VERSION ""

NS_ :

BS_:

BU_: TBox

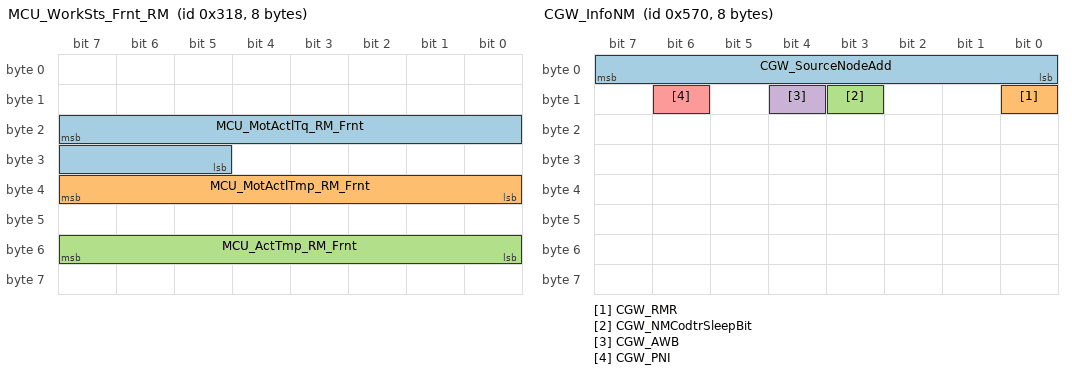
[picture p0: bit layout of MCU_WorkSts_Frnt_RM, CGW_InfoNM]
BO_ 792 MCU_WorkSts_Frnt_RM: 8 CGW
 SG_ MCU_MotActlTq_RM_Frnt : 23|11@0+ (0.5,-500) [-500|500] "Nm" TBox
 SG_ MCU_MotActlTmp_RM_Frnt : 39|8@0+ (1,-40) [-40|214] "degree C" TBox
 SG_ MCU_ActTmp_RM_Frnt : 55|8@0+ (1,-40) [-40|214] "degree C" TBox

BO_ 1392 CGW_InfoNM: 8 CGW
 SG_ CGW_SourceNodeAdd : 7|8@0+ (1,0) [112|112] "" TBox,HU,AMP
 SG_ CGW_RMR : 8|1@0+ (1,0) [0|1] "" TBox,HU,AMP
 SG_ CGW_NMCodtrSleepBit : 11|1@0+ (1,0) [0|1] "" TBox,HU,AMP
 SG_ CGW_AWB : 12|1@0+ (1,0) [0|1] "" TBox,HU,AMP
 SG_ CGW_PNI : 14|1@0+ (1,0) [0|1] "" TBox,HU,AMP

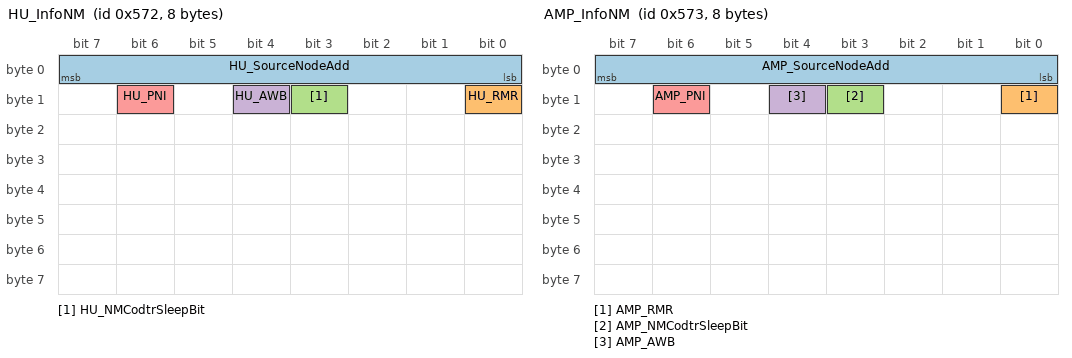
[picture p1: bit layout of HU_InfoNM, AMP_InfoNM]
BO_ 1394 HU_InfoNM: 8 HU
 SG_ HU_SourceNodeAdd : 7|8@0+ (1,0) [114|114] "" TBox,AMP,CGW
 SG_ HU_RMR : 8|1@0+ (1,0) [0|1] "" TBox,AMP,CGW
 SG_ HU_NMCodtrSleepBit : 11|1@0+ (1,0) [0|1] "" TBox,AMP,CGW
 SG_ HU_AWB : 12|1@0+ (1,0) [0|1] "" TBox,AMP,CGW
 SG_ HU_PNI : 14|1@0+ (1,0) [0|1] "" TBox,AMP,CGW

BO_ 1395 AMP_InfoNM: 8 AMP
 SG_ AMP_SourceNodeAdd : 7|8@0+ (1,0) [115|115] "" TBox,HU,CGW
 SG_ AMP_RMR : 8|1@0+ (1,0) [0|1] "" TBox,HU,CGW
 SG_ AMP_NMCodtrSleepBit : 11|1@0+ (1,0) [0|1] "" TBox,HU,CGW
 SG_ AMP_AWB : 12|1@0+ (1,0) [0|1] "" TBox,HU,CGW
 SG_ AMP_PNI : 14|1@0+ (1,0) [0|1] "" TBox,HU,CGW

BO_ 284 VCU_HUDisp_1: 8 CGW
 SG_ VCU_ChrgStsIndcr : 7|1@0+ (1,0) [0|1] "" TBox,HU,AMP
 SG_ VCU_ChrgConnectIndcr : 6|1@0+ (1,0) [0|1] "" TBox,HU

BO_ 285 VCU_HUDisp_2: 8 CGW
 SG_ VCU_VhclResidualMile : 7|10@0+ (1,0) [0|600] "km" TBox,HU

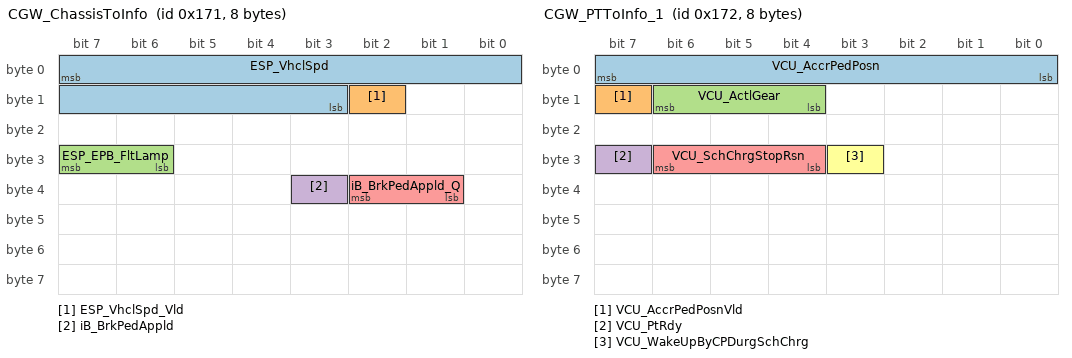
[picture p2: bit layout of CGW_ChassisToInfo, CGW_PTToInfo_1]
BO_ 369 CGW_ChassisToInfo: 8 CGW
 SG_ ESP_VhclSpd : 7|13@0+ (0.05625,0) [0|300] "km/h" TBox,HU,AMP,PAS
 SG_ ESP_VhclSpd_Vld : 10|1@0+ (1,0) [0|1] "" TBox,HU,AMP,PAS
 SG_ ESP_EPB_FltLamp : 31|2@0+ (1,0) [0|3] "" TBox,HU,PAS
 SG_ iB_BrkPedAppld : 35|1@0+ (1,0) [0|1] "" TBox
 SG_ iB_BrkPedAppld_Q : 34|2@0+ (1,0) [0|3] "" TBox

BO_ 370 CGW_PTToInfo_1: 8 CGW
 SG_ VCU_AccrPedPosn : 7|8@0+ (0.4,0) [0|100] "%" TBox
 SG_ VCU_AccrPedPosnVld : 15|1@0+ (1,0) [0|1] "" TBox
 SG_ VCU_ActlGear : 14|3@0+ (1,0) [0|7] "" TBox,HU,AMP,PAS
 SG_ VCU_PtRdy : 31|1@0+ (1,0) [0|1] "" TBox,HU,AMP,PAS
 SG_ VCU_SchChrgStopRsn : 30|3@0+ (1,0) [0|7] "" TBox,HU
 SG_ VCU_WakeUpByCPDurgSchChrg : 27|1@0+ (1,0) [0|1] "" TBox

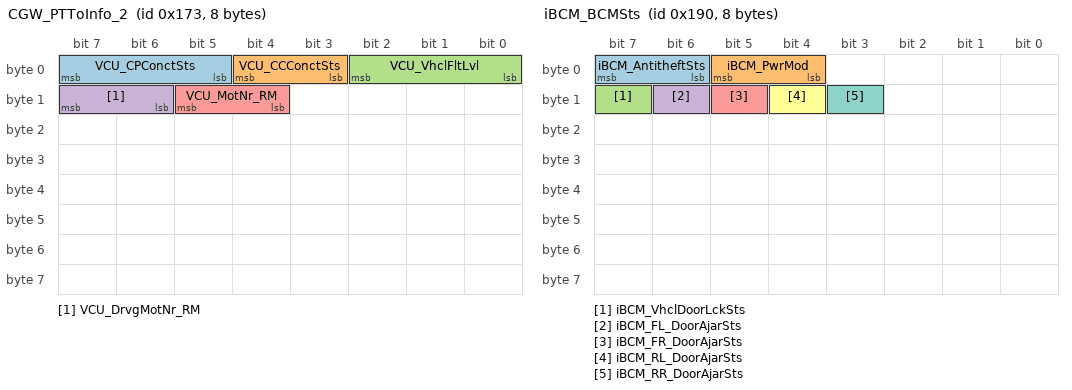
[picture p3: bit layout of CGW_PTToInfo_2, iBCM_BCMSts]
BO_ 371 CGW_PTToInfo_2: 8 CGW
 SG_ VCU_CPConctSts : 7|3@0+ (1,0) [0|7] "" TBox
 SG_ VCU_CCConctSts : 4|2@0+ (1,0) [0|3] "" TBox
 SG_ VCU_VhclFltLvl : 2|3@0+ (1,0) [0|7] "" TBox,HU
 SG_ VCU_DrvgMotNr_RM : 15|2@0+ (1,0) [0|3] "" TBox
 SG_ VCU_MotNr_RM : 13|2@0+ (1,0) [0|3] "" TBox

BO_ 400 iBCM_BCMSts: 8 CGW
 SG_ iBCM_AntitheftSts : 7|2@0+ (1,0) [0|3] "" TBox,HU
 SG_ iBCM_PwrMod : 5|2@0+ (1,0) [0|3] "" TBox,HU,PAS
 SG_ iBCM_VhclDoorLckSts : 15|1@0+ (1,0) [0|1] "" TBox,HU
 SG_ iBCM_FL_DoorAjarSts : 14|1@0+ (1,0) [0|1] "" TBox,HU
 SG_ iBCM_FR_DoorAjarSts : 13|1@0+ (1,0) [0|1] "" TBox,HU
 SG_ iBCM_RL_DoorAjarSts : 12|1@0+ (1,0) [0|1] "" TBox,HU
 SG_ iBCM_RR_DoorAjarSts : 11|1@0+ (1,0) [0|1] "" TBox,HU

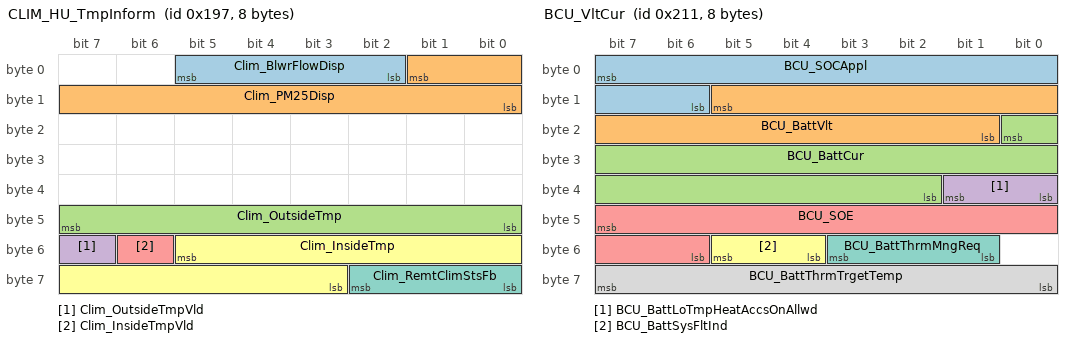
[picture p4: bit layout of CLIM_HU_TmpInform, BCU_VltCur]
BO_ 407 CLIM_HU_TmpInform: 8 CGW
 SG_ Clim_BlwrFlowDisp : 5|4@0+ (1,0) [0|15] "" TBox,HU
 SG_ Clim_PM25Disp : 1|10@0+ (1,0) [0|999] "ug/m3" TBox,HU
 SG_ Clim_OutsideTmp : 47|8@0+ (1,-40) [-40|215] "℃" TBox,PAS
 SG_ Clim_OutsideTmpVld : 55|1@0+ (1,0) [0|1] "" TBox,PAS
 SG_ Clim_InsideTmpVld : 54|1@0+ (1,0) [0|1] "" TBox
 SG_ Clim_InsideTmp : 53|11@0+ (0.1,-40) [-40|120] "℃" TBox
 SG_ Clim_RemtClimStsFb : 58|3@0+ (1,0) [0|7] "" TBox

BO_ 529 BCU_VltCur: 8 CGW
 SG_ BCU_SOCAppl : 7|10@0+ (0.1,0) [0|100] "%" TBox
 SG_ BCU_BattVlt : 13|13@0+ (0.1,0) [0|500] "V" TBox,HU
 SG_ BCU_BattCur : 16|15@0+ (0.1,-1200) [-1200|1200] "A" TBox,HU
 SG_ BCU_BattLoTmpHeatAccsOnAllwd : 33|2@0+ (1,0) [0|3] "" TBox
 SG_ BCU_SOE : 47|10@0+ (0.1,0) [0|100] "%" TBox
 SG_ BCU_BattSysFltInd : 53|2@0+ (1,0) [0|3] "" TBox
 SG_ BCU_BattThrmMngReq : 51|3@0+ (1,0) [0|7] "" TBox
 SG_ BCU_BattThrmTrgetTemp : 63|8@0+ (1,-40) [-40|120] "℃" TBox

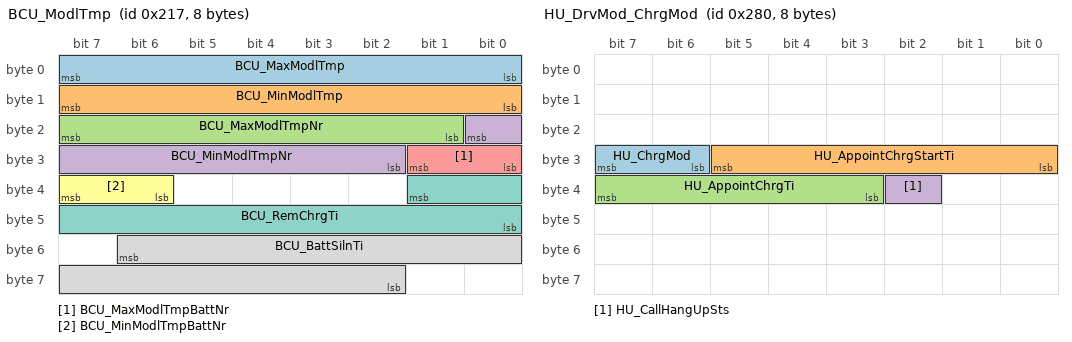
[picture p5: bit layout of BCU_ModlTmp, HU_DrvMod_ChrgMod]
BO_ 535 BCU_ModlTmp: 8 CGW
 SG_ BCU_MaxModlTmp : 7|8@0+ (1,-40) [-40|120] "℃" TBox
 SG_ BCU_MinModlTmp : 15|8@0+ (1,-40) [-40|120] "℃" TBox
 SG_ BCU_MaxModlTmpNr : 23|7@0+ (1,0) [0|120] "" TBox
 SG_ BCU_MinModlTmpNr : 16|7@0+ (1,0) [0|120] "" TBox
 SG_ BCU_MaxModlTmpBattNr : 25|2@0+ (1,0) [0|3] "" TBox
 SG_ BCU_MinModlTmpBattNr : 39|2@0+ (1,0) [0|3] "" TBox
 SG_ BCU_RemChrgTi : 33|10@0+ (1,0) [0|1023] "min" TBox,HU
 SG_ BCU_BattSilnTi : 54|13@0+ (0.1,0) [0|800] "min" TBox

BO_ 536 BCU_WarnInfo: 8 CGW
 SG_ BCU_REESSFaultNr_RM : 7|8@0+ (1,0) [0|254] "" TBox
 SG_ BCU_SOH : 14|7@0+ (1,0) [0|100] "%" TBox
 SG_ BCU_BattOverTmp : 15|1@0+ (1,0) [0|1] "" TBox,HU
 SG_ BCU_CellTmpOverWarn : 16|1@0+ (1,0) [0|1] "" TBox
 SG_ BCU_CellVltUdrWarn : 17|1@0+ (1,0) [0|1] "" TBox
 SG_ BCU_CellVltOverWarn : 18|1@0+ (1,0) [0|1] "" TBox
 SG_ BCU_BattTmpDftlWarn : 19|1@0+ (1,0) [0|1] "" TBox
 SG_ BCU_CellTmpUdrWarn : 20|1@0+ (1,0) [0|1] "" TBox
 SG_ BCU_BattVltUnifWarn : 21|1@0+ (1,0) [0|1] "" TBox
 SG_ BCU_BattVltDftlOverRg : 22|1@0+ (1,0) [0|1] "" TBox
 SG_ BCU_BattVltUdrWarn : 23|1@0+ (1,0) [0|1] "" TBox
 SG_ BCU_BattVltOverWarn : 24|1@0+ (1,0) [0|1] "" TBox
 SG_ BCU_NvMemSts : 25|1@0+ (1,0) [0|1] "" TBox
 SG_ BCU_SOCJumpWarn : 26|1@0+ (1,0) [0|1] "" TBox
 SG_ BCU_SOCOverWarn : 27|1@0+ (1,0) [0|1] "" TBox
 SG_ BCU_SOCLowWarn : 28|1@0+ (1,0) [0|1] "" TBox
 SG_ BCU_BattTmpDftlWarn_RM : 29|1@0+ (1,0) [0|1] "" TBox
 SG_ BCU_REESSNotMatch_RM : 30|1@0+ (1,0) [0|1] "" TBox
 SG_ BCU_OverChrgWarn_RM : 31|1@0+ (1,0) [0|1] "" TBox
 SG_ BCU_ACChrgCntr : 45|11@0+ (1,0) [0|2000] "" TBox
 SG_ BCU_DCChrgrCntr : 50|11@0+ (1,0) [0|2000] "" TBox

BO_ 640 HU_DrvMod_ChrgMod: 8 HU
 SG_ HU_ChrgMod : 31|2@0+ (1,0) [0|3] "" TBox
 SG_ HU_AppointChrgStartTi : 29|6@0+ (1,0) [0|47] "" TBox
 SG_ HU_AppointChrgTi : 39|5@0+ (1,0) [0|23] "" TBox
 SG_ HU_CallHangUpSts : 34|1@0+ (1,0) [0|1] "" TBox

BO_ 641 HU_ESPSwch: 8 HU
 SG_ HU_TotlOdo : 47|24@0+ (0.1,0) [0|999999.9] "km" TBox,CGW

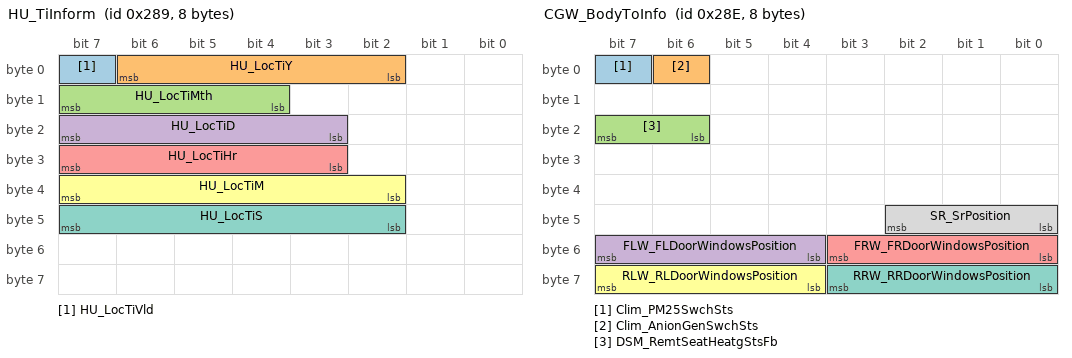
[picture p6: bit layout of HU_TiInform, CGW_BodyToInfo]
BO_ 649 HU_TiInform: 8 HU
 SG_ HU_LocTiVld : 7|1@0+ (1,0) [0|1] "" TBox,CGW
 SG_ HU_LocTiY : 6|5@0+ (1,2019) [2019|2050] "year" TBox,CGW
 SG_ HU_LocTiMth : 15|4@0+ (1,0) [1|12] "month" TBox,CGW
 SG_ HU_LocTiD : 23|5@0+ (1,0) [1|31] "day" TBox,CGW
 SG_ HU_LocTiHr : 31|5@0+ (1,0) [0|23] "hour" TBox,CGW
 SG_ HU_LocTiM : 39|6@0+ (1,0) [0|59] "minute" TBox,CGW
 SG_ HU_LocTiS : 47|6@0+ (1,0) [0|59] "second" TBox,CGW

BO_ 654 CGW_BodyToInfo: 8 CGW
 SG_ Clim_PM25SwchSts : 7|1@0+ (1,0) [0|1] "" TBox
 SG_ Clim_AnionGenSwchSts : 6|1@0+ (1,0) [0|1] "" TBox
 SG_ DSM_RemtSeatHeatgStsFb : 23|2@0+ (1,0) [0|3] "" TBox
 SG_ FLW_FLDoorWindowsPosition : 55|4@0+ (1,0) [0|15] "" TBox,HU
 SG_ FRW_FRDoorWindowsPosition : 51|4@0+ (1,0) [0|15] "" TBox,HU
 SG_ RLW_RLDoorWindowsPosition : 63|4@0+ (1,0) [0|15] "" TBox,HU
 SG_ RRW_RRDoorWindowsPosition : 59|4@0+ (1,0) [0|15] "" TBox,HU
 SG_ SR_SrPosition : 42|3@0+ (1,0) [0|7] "" TBox,HU

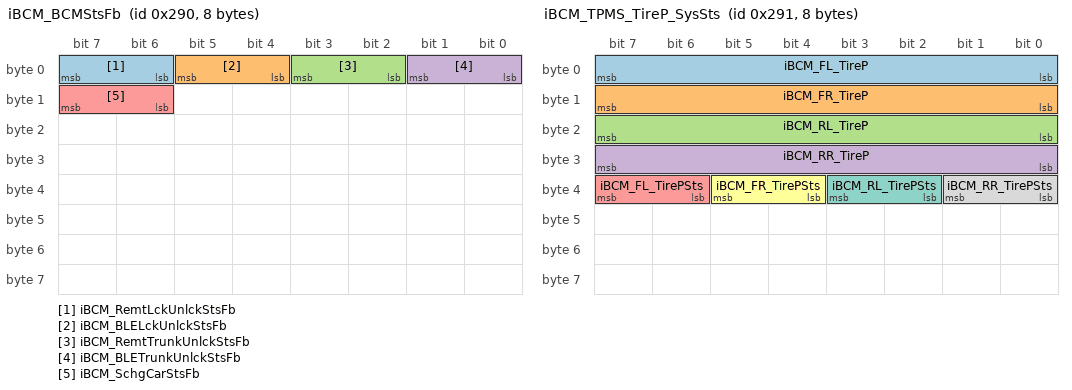
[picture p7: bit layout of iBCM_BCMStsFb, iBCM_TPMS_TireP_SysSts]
BO_ 656 iBCM_BCMStsFb: 8 CGW
 SG_ iBCM_RemtLckUnlckStsFb : 7|2@0+ (1,0) [0|3] "" TBox
 SG_ iBCM_BLELckUnlckStsFb : 5|2@0+ (1,0) [0|3] "" TBox
 SG_ iBCM_RemtTrunkUnlckStsFb : 3|2@0+ (1,0) [0|3] "" TBox
 SG_ iBCM_BLETrunkUnlckStsFb : 1|2@0+ (1,0) [0|3] "" TBox
 SG_ iBCM_SchgCarStsFb : 15|2@0+ (1,0) [0|3] "" TBox

BO_ 657 iBCM_TPMS_TireP_SysSts: 8 CGW
 SG_ iBCM_FL_TireP : 7|8@0+ (1.373,0) [0|348.742] "kpa" TBox,HU
 SG_ iBCM_FR_TireP : 15|8@0+ (1.373,0) [0|348.742] "kpa" TBox,HU
 SG_ iBCM_RL_TireP : 23|8@0+ (1.373,0) [0|348.742] "kpa" TBox,HU
 SG_ iBCM_RR_TireP : 31|8@0+ (1.373,0) [0|348.742] "kpa" TBox,HU
 SG_ iBCM_FL_TirePSts : 39|2@0+ (1,0) [0|3] "" TBox,HU
 SG_ iBCM_FR_TirePSts : 37|2@0+ (1,0) [0|3] "" TBox,HU
 SG_ iBCM_RL_TirePSts : 35|2@0+ (1,0) [0|3] "" TBox,HU
 SG_ iBCM_RR_TirePSts : 33|2@0+ (1,0) [0|3] "" TBox,HU

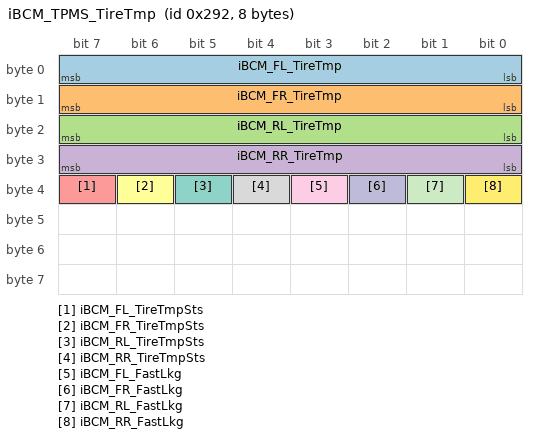
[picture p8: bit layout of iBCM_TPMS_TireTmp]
BO_ 658 iBCM_TPMS_TireTmp: 8 CGW
 SG_ iBCM_FL_TireTmp : 7|8@0+ (1,-50) [-50|204] "℃" TBox,HU
 SG_ iBCM_FR_TireTmp : 15|8@0+ (1,-50) [-50|204] "℃" TBox,HU
 SG_ iBCM_RL_TireTmp : 23|8@0+ (1,-50) [-50|204] "℃" TBox,HU
 SG_ iBCM_RR_TireTmp : 31|8@0+ (1,-50) [-50|204] "℃" TBox,HU
 SG_ iBCM_FL_TireTmpSts : 39|1@0+ (1,0) [0|1] "" TBox,HU
 SG_ iBCM_FR_TireTmpSts : 38|1@0+ (1,0) [0|1] "" TBox,HU
 SG_ iBCM_RL_TireTmpSts : 37|1@0+ (1,0) [0|1] "" TBox,HU
 SG_ iBCM_RR_TireTmpSts : 36|1@0+ (1,0) [0|1] "" TBox,HU
 SG_ iBCM_FL_FastLkg : 35|1@0+ (1,0) [0|1] "" TBox,HU
 SG_ iBCM_FR_FastLkg : 34|1@0+ (1,0) [0|1] "" TBox,HU
 SG_ iBCM_RL_FastLkg : 33|1@0+ (1,0) [0|1] "" TBox,HU
 SG_ iBCM_RR_FastLkg : 32|1@0+ (1,0) [0|1] "" TBox,HU

CM_ SG_ 640 HU_ChrgMod "HU_ChargeMode
充电模式";
CM_ SG_ 640 HU_AppointChrgStartTi "HU_AppointChargeStartTime
充电预约开始时间";
CM_ SG_ 640 HU_AppointChrgTi "HU_AppointChargeTime
预约充电时长";
CM_ SG_ 640 HU_CallHangUpSts "HU_CallHangUpStatus
电话挂断状态";
CM_ SG_ 641 HU_TotlOdo "HU_TotalOdometer
累计里程";
CM_ SG_ 649 HU_LocTiVld "HU_LocalTimeValid
本地时间有效位";
CM_ SG_ 649 HU_LocTiY "HU_LocalTimeYear
本地时间年";
CM_ SG_ 649 HU_LocTiMth "HU_LocalTimeMonth
本地时间月";
CM_ SG_ 649 HU_LocTiD "HU_LocalTimeDay
本地时间日";
CM_ SG_ 649 HU_LocTiHr "HU_LocalTimeHour
本地时间时";
CM_ SG_ 649 HU_LocTiM "HU_LocalTimeMinute
本地时间分";
CM_ SG_ 649 HU_LocTiS "HU_LocalTimeSecond
本地时间秒";
CM_ SG_ 1394 HU_SourceNodeAdd "Source Node Address
原节点地址";
CM_ SG_ 1394 HU_RMR "Repeat message request
重复报文请求";
CM_ SG_ 1394 HU_NMCodtrSleepBit "NM Coordinator Sleep Bit
网络管理协调睡眠指示位";
CM_ SG_ 1394 HU_AWB "Active wakeup bit
主动唤醒指示位";
CM_ SG_ 1394 HU_PNI "Partial netwark information bit 
局部网络指示位";
CM_ SG_ 1395 AMP_SourceNodeAdd "Source Node Address
原节点地址";
CM_ SG_ 1395 AMP_RMR "Repeat message request
重复报文请求";
CM_ SG_ 1395 AMP_NMCodtrSleepBit "NM Coordinator Sleep Bit
网络管理协调睡眠指示位";
CM_ SG_ 1395 AMP_AWB "Active wakeup bit
主动唤醒指示位";
CM_ SG_ 1395 AMP_PNI "Partial netwark information bit 
局部网络指示位";
CM_ SG_ 1392 CGW_SourceNodeAdd "Source Node Address
原节点地址";
CM_ SG_ 1392 CGW_RMR "Repeat message request
重复报文请求";
CM_ SG_ 1392 CGW_NMCodtrSleepBit "NM Coordinator Sleep Bit
网络管理协调睡眠指示位";
CM_ SG_ 1392 CGW_AWB "Active wakeup bit
主动唤醒指示位";
CM_ SG_ 1392 CGW_PNI "Partial netwark information bit 
局部网络指示位";
CM_ SG_ 284 VCU_ChrgStsIndcr "Charge status indicator
充电状态指示";
CM_ SG_ 284 VCU_ChrgConnectIndcr "Charge connect indicator
充电链接指示";
CM_ SG_ 285 VCU_VhclResidualMile "Vehicle residual mileage
剩余续驶里程";
CM_ SG_ 370 VCU_AccrPedPosn "Accelerator Pedal Position";
CM_ SG_ 370 VCU_AccrPedPosnVld "Accelerator Pedal Position Valid";
CM_ SG_ 370 VCU_ActlGear "Actual gear";
CM_ SG_ 370 VCU_PtRdy "Powertrain have ready
动力系统准备就绪";
CM_ SG_ 370 VCU_SchChrgStopRsn "Schedule charging stop reason
预约充电停止充电的原因";
CM_ SG_ 370 VCU_WakeUpByCPDurgSchChrg "VCU is wake up by CP when power net is recovery during schedule charging
预约充电中电网断电再次来电VCU被CP唤醒(仅用于该工况)";
CM_ SG_ 371 VCU_CPConctSts "CP Connection Status
CP状态";
CM_ SG_ 371 VCU_CCConctSts "CC Connection Status
CC状态";
CM_ SG_ 371 VCU_VhclFltLvl "Vehicle Fault Level
整车故障等级";
CM_ SG_ 371 VCU_DrvgMotNr_RM "Driving motor number
驱动电机号";
CM_ SG_ 371 VCU_MotNr_RM "Motor number
电机数量";
CM_ SG_ 792 MCU_MotActlTq_RM_Frnt "Motor actual torque
电机实际扭矩";
CM_ SG_ 792 MCU_MotActlTmp_RM_Frnt "Actual temperature of motor
电机实际温度";
CM_ SG_ 792 MCU_ActTmp_RM_Frnt "MCU actual temperature
电机控制器实际温度";
CM_ SG_ 529 BCU_SOCAppl "Application SOC
电池荷电量(应用SOC)";
CM_ SG_ 529 BCU_BattVlt "Battery Voltage
电池总电压";
CM_ SG_ 529 BCU_BattCur "Battery current
电池总电流";
CM_ SG_ 529 BCU_BattLoTmpHeatAccsOnAllwd "Battery low temperature heating accessory on allowed
电池低温加热附件开启允许";
CM_ SG_ 529 BCU_SOE "SOE
电池剩余电量";
CM_ SG_ 529 BCU_BattSysFltInd "Battery systerm fault indicate
电池系统故障";
CM_ SG_ 529 BCU_BattThrmMngReq "Battery Thermo Management request
电池热管理请求";
CM_ SG_ 529 BCU_BattThrmTrgetTemp "Battery Thermo target temperature
电池热管理目标温度";
CM_ SG_ 535 BCU_MaxModlTmp "Module Max Tempeture
模组最高温度";
CM_ SG_ 535 BCU_MinModlTmp "Module Min Tempeture
模组最低温度";
CM_ SG_ 535 BCU_MaxModlTmpNr "Max module tempeture number
模组最高温度对应的编号";
CM_ SG_ 535 BCU_MinModlTmpNr "Min module tempeture number
模组最低温度对应的编号";
CM_ SG_ 535 BCU_MaxModlTmpBattNr "Max module tempeture battery number
模组最高温度对应点的电池编号";
CM_ SG_ 535 BCU_MinModlTmpBattNr "Min module tempeture battery number
模组最低温度对应点的电池编号";
CM_ SG_ 535 BCU_RemChrgTi "Remain Charging Time
剩余充电时间";
CM_ SG_ 535 BCU_BattSilnTi "Battery Silence Time 
电池静置时间";
CM_ SG_ 536 BCU_REESSFaultNr_RM "Falut number of rechargeable electrical energy storage systerm
可充电储能设备故障总数";
CM_ SG_ 536 BCU_SOH "SOH
电池健康状态";
CM_ SG_ 536 BCU_BattOverTmp "Battery Over Tempeture Waring
动力电池过温报警";
CM_ SG_ 536 BCU_CellTmpOverWarn "Cell Over Tempeture Warning
单体电池温度过高报警";
CM_ SG_ 536 BCU_CellVltUdrWarn "Cell Voltage Under Warning
单体电池欠压报警";
CM_ SG_ 536 BCU_CellVltOverWarn "Cell Voltage Over Warning
单体电池过压报警";
CM_ SG_ 536 BCU_BattTmpDftlWarn "Battery Tempeture Differential Warning
温度差异报警";
CM_ SG_ 536 BCU_CellTmpUdrWarn "Cell Under Tempeture Warning
单体电池温度过低报警";
CM_ SG_ 536 BCU_BattVltUnifWarn "Battery Voltage Uniformity Warning
动力蓄电池一致性差报警";
CM_ SG_ 536 BCU_BattVltDftlOverRg "Battery Voltage Diff Over Range
单体压差过大";
CM_ SG_ 536 BCU_BattVltUdrWarn "Battery Voltage Under Warning
动力电池欠压报警";
CM_ SG_ 536 BCU_BattVltOverWarn "Battery Voltage Over Warning
动力电池过压报警";
CM_ SG_ 536 BCU_NvMemSts "Nonvolatile Memory Status
非易失性存储器状态";
CM_ SG_ 536 BCU_SOCJumpWarn "SOC Jump Warning
SOC跳变报警";
CM_ SG_ 536 BCU_SOCOverWarn "SOC Over Warning
SOC过高报警";
CM_ SG_ 536 BCU_SOCLowWarn "SOC Low Warning
SOC过低报警";
CM_ SG_ 536 BCU_BattTmpDftlWarn_RM "Battery Tempeture Differential Warning
电池温度差异报警";
CM_ SG_ 536 BCU_REESSNotMatch_RM "Rechargeable electrical energy storage systerm not match
可充电储能系统不匹配";
CM_ SG_ 536 BCU_OverChrgWarn_RM "Over charging warning 
过充报警";
CM_ SG_ 536 BCU_ACChrgCntr "AC Charge Counter
慢充累计次数";
CM_ SG_ 536 BCU_DCChrgrCntr "DC Charger Counter
快充累计次数";
CM_ SG_ 369 ESP_VhclSpd "Vehicle speed out";
CM_ SG_ 369 ESP_VhclSpd_Vld "Vehicle speed out status";
CM_ SG_ 369 ESP_EPB_FltLamp "EPB_FailureLamp";
CM_ SG_ 369 iB_BrkPedAppld "Brake pedal is applied";
CM_ SG_ 369 iB_BrkPedAppld_Q "Qualifier of brake pedal applied";
CM_ SG_ 657 iBCM_FL_TireP "TireLeftFrontPressure
左前轮胎压压力";
CM_ SG_ 657 iBCM_FR_TireP "TireRightFrontPressure
右前轮胎压压力";
CM_ SG_ 657 iBCM_RL_TireP "TireLeftRearPressure
左后轮胎压压力";
CM_ SG_ 657 iBCM_RR_TireP "TireRightRearPressure
右后轮胎压压力";
CM_ SG_ 657 iBCM_FL_TirePSts "TireLeftFrontPressureStatus
左前轮胎压状态";
CM_ SG_ 657 iBCM_FR_TirePSts "TireRightFrontPressureStatus
右前轮胎压状态";
CM_ SG_ 657 iBCM_RL_TirePSts "TireLeftRearPressureStatus
左后轮胎压状态";
CM_ SG_ 657 iBCM_RR_TirePSts "TireRightRearPressureStatus
右后轮胎压状态";
CM_ SG_ 658 iBCM_FL_TireTmp "TireLeftFrontTemperature
左前轮胎温";
CM_ SG_ 658 iBCM_FR_TireTmp "TireRightFrontTemperature
右前轮胎温";
CM_ SG_ 658 iBCM_RL_TireTmp "TireLeftRearTemperature
左后轮胎温";
CM_ SG_ 658 iBCM_RR_TireTmp "TireRightRearTemperature
右后轮胎温";
CM_ SG_ 658 iBCM_FL_TireTmpSts "TireLeftFrontTemperatureStatus
左前轮轮胎温状态";
CM_ SG_ 658 iBCM_FR_TireTmpSts "TireRightFrontTemperatureStatus
右前轮轮胎温状态";
CM_ SG_ 658 iBCM_RL_TireTmpSts "TireLeftRearTemperatureStatus
左后轮轮胎温状态";
CM_ SG_ 658 iBCM_RR_TireTmpSts "TireRightRearTemperatureStatus
右后轮轮胎温状态";
CM_ SG_ 658 iBCM_FL_FastLkg "Tire Front Left FastLeakage
左前轮快速漏气(预留)";
CM_ SG_ 658 iBCM_FR_FastLkg "Tire Front Right FastLeakage
右前轮快速漏气(预留)";
CM_ SG_ 658 iBCM_RL_FastLkg "Tire Rear Left FastLeakage
左后轮快速漏气(预留)";
CM_ SG_ 658 iBCM_RR_FastLkg "Tire Rear Right Fast Leakage
右后轮快速漏气(预留)";
CM_ SG_ 656 iBCM_RemtLckUnlckStsFb "TBox_RemoteLockUnlckStatusFeedback
远程解闭锁状态反馈";
CM_ SG_ 656 iBCM_BLELckUnlckStsFb "TBox_BLELockUnlockStatusFeedback
蓝牙解闭锁状态反馈";
CM_ SG_ 656 iBCM_RemtTrunkUnlckStsFb "TBox_RemoteTrunkUnlockStatusFeedback
远程后备箱解锁状态反馈";
CM_ SG_ 656 iBCM_BLETrunkUnlckStsFb "TBox_BLETrunkUnlockStatusFeedback
蓝牙后备箱解锁状态反馈";
CM_ SG_ 656 iBCM_SchgCarStsFb "TBox_SearchingCarReqStatusFeedback
寻车请求状态反馈";
CM_ SG_ 407 Clim_BlwrFlowDisp "Blower Air Flow display
鼓风机风量显示";
CM_ SG_ 407 Clim_PM25Disp "PM2.5 display
PM2.5显示";
CM_ SG_ 407 Clim_OutsideTmp "Out-Car temperature 
车外温度";
CM_ SG_ 407 Clim_OutsideTmpVld "Out-car temperature Validity
车外温度有效性";
CM_ SG_ 407 Clim_InsideTmpVld "In-car temperature Validity
车内温度有效性";
CM_ SG_ 407 Clim_InsideTmp "In-Car temperature 
车内温度";
CM_ SG_ 407 Clim_RemtClimStsFb "Remote Climate Status Feedback
远程空调状态反馈
";
CM_ SG_ 654 Clim_PM25SwchSts "PM2.5 Switch State Signal 
PM2.5开关状态信号";
CM_ SG_ 654 Clim_AnionGenSwchSts "Negative Ion Generator Switch State Signal 
负离子发生器开关状态信号";
CM_ SG_ 654 DSM_RemtSeatHeatgStsFb "Remote Seat Heating Status Feedback
远程座椅加热状态反馈
";
CM_ SG_ 654 FLW_FLDoorWindowsPosition "Left front window position 
左前车窗位置";
CM_ SG_ 654 FRW_FRDoorWindowsPosition "Right front window position 
右前车窗位置";
CM_ SG_ 654 RLW_RLDoorWindowsPosition "Left rear window position
左后车窗位置";
CM_ SG_ 654 RRW_RRDoorWindowsPosition "Rignt rear window position
右后车窗位置";
CM_ SG_ 654 SR_SrPosition "Sunroof position
天窗位置";
CM_ SG_ 400 iBCM_AntitheftSts "Vehicle Antitheft Status
防盗报警状态";
CM_ SG_ 400 iBCM_PwrMod "Power Mode
系统电源";
CM_ SG_ 400 iBCM_VhclDoorLckSts "Vehicle Door Lock Status
整车门锁状态";
CM_ SG_ 400 iBCM_FL_DoorAjarSts "Driver Door Ajar Status
驾驶侧门开关状态";
CM_ SG_ 400 iBCM_FR_DoorAjarSts "Passenger Door Ajar Status
副驾驶侧门开关状态";
CM_ SG_ 400 iBCM_RL_DoorAjarSts "Rear Left Door Ajar Status
左后门开关状态";
CM_ SG_ 400 iBCM_RR_DoorAjarSts "Rear Right Door Ajar Status
右后门开关状态";

BA_DEF_ BO_  "NmMessage" ENUM "No","Yes";
BA_DEF_ BO_  "GenMsgSendType" ENUM  "Cycle","NoSendType","IfActive";
BA_DEF_ BO_  "GenMsgCycleTime" INT 0 0;
BA_DEF_ SG_  "GenSigSendType" ENUM  "Cycle","OnChange","OnWrite","IfActive","OnChangeWithRepetition","OnWriteWithRepetition","IfActiveWithRepetition";
BA_DEF_ SG_  "GenSigStartValue" INT 0 0;
BA_DEF_ BO_  "GenMsgCycleTimeFast" INT 0 0;
BA_DEF_ BO_  "GenMsgNrOfRepetition" INT 0 0;
BA_DEF_ BO_  "GenMsgDelayTime" INT 0 0;
BA_DEF_ BO_  "VFrameFormat" ENUM  "StandardCAN","ExtendedCAN","reserved","reserved","reserved","reserved","reserved","reserved","reserved","reserved","reserved","reserved","reserved","reserved","StandardCAN_FD","ExtendedCAN_FD";

BA_DEF_DEF_  "NmMessage" "No";
BA_DEF_DEF_  "GenMsgSendType" "Cycle";
BA_DEF_DEF_  "GenMsgCycleTime" 0;
BA_DEF_DEF_  "GenSigSendType" "Cycle";
BA_DEF_DEF_  "GenSigStartValue" 0;
BA_DEF_DEF_  "GenMsgCycleTimeFast" 0;
BA_DEF_DEF_  "GenMsgNrOfRepetition" 0;
BA_DEF_DEF_  "GenMsgDelayTime" 0;
BA_DEF_DEF_  "VFrameFormat" "StandardCAN";
BA_ "GenSigStartValue" SG_ 792 MCU_MotActlTq_RM_Frnt 1000;
BA_ "GenSigStartValue" SG_ 792 MCU_MotActlTmp_RM_Frnt 40;
BA_ "GenSigStartValue" SG_ 792 MCU_ActTmp_RM_Frnt 40;
BA_ "NmMessage" BO_ 1392 1;
BA_ "GenMsgCycleTime" BO_ 1392 500;
BA_ "GenMsgCycleTimeFast" BO_ 1392 10;
BA_ "GenMsgNrOfRepetition" BO_ 1392 5;
BA_ "GenSigSendType" SG_ 1392 CGW_SourceNodeAdd 6;
BA_ "GenSigStartValue" SG_ 1392 CGW_SourceNodeAdd 112;
BA_ "GenSigSendType" SG_ 1392 CGW_RMR 6;
BA_ "GenSigSendType" SG_ 1392 CGW_NMCodtrSleepBit 6;
BA_ "GenSigSendType" SG_ 1392 CGW_AWB 6;
BA_ "GenSigSendType" SG_ 1392 CGW_PNI 6;
BA_ "NmMessage" BO_ 1394 1;
BA_ "GenMsgCycleTime" BO_ 1394 500;
BA_ "GenMsgCycleTimeFast" BO_ 1394 10;
BA_ "GenMsgNrOfRepetition" BO_ 1394 5;
BA_ "GenSigSendType" SG_ 1394 HU_SourceNodeAdd 6;
BA_ "GenSigStartValue" SG_ 1394 HU_SourceNodeAdd 114;
BA_ "GenSigSendType" SG_ 1394 HU_RMR 6;
BA_ "GenSigSendType" SG_ 1394 HU_NMCodtrSleepBit 6;
BA_ "GenSigSendType" SG_ 1394 HU_AWB 6;
BA_ "GenSigSendType" SG_ 1394 HU_PNI 6;
BA_ "NmMessage" BO_ 1395 1;
BA_ "GenMsgCycleTime" BO_ 1395 500;
BA_ "GenMsgCycleTimeFast" BO_ 1395 10;
BA_ "GenMsgNrOfRepetition" BO_ 1395 5;
BA_ "GenSigSendType" SG_ 1395 AMP_SourceNodeAdd 6;
BA_ "GenSigStartValue" SG_ 1395 AMP_SourceNodeAdd 115;
BA_ "GenSigSendType" SG_ 1395 AMP_RMR 6;
BA_ "GenSigSendType" SG_ 1395 AMP_NMCodtrSleepBit 6;
BA_ "GenSigSendType" SG_ 1395 AMP_AWB 6;
BA_ "GenSigSendType" SG_ 1395 AMP_PNI 6;
BA_ "GenMsgCycleTime" BO_ 284 100;
BA_ "GenMsgCycleTime" BO_ 285 100;
BA_ "GenMsgCycleTime" BO_ 369 20;
BA_ "GenMsgCycleTime" BO_ 370 50;
BA_ "GenMsgCycleTime" BO_ 371 50;
BA_ "GenMsgCycleTime" BO_ 400 100;
BA_ "GenMsgCycleTime" BO_ 407 50;
BA_ "GenSigStartValue" SG_ 407 Clim_PM25Disp 1000;
BA_ "GenMsgCycleTime" BO_ 529 10;
BA_ "GenSigStartValue" SG_ 529 BCU_BattCur 12000;
BA_ "GenSigStartValue" SG_ 529 BCU_BattThrmTrgetTemp 40;
BA_ "GenMsgCycleTime" BO_ 535 1000;
BA_ "GenSigStartValue" SG_ 535 BCU_MaxModlTmp 40;
BA_ "GenSigStartValue" SG_ 535 BCU_MinModlTmp 40;
BA_ "GenMsgCycleTime" BO_ 536 1000;
BA_ "GenMsgCycleTime" BO_ 640 100;
BA_ "GenMsgCycleTime" BO_ 641 50;
BA_ "GenMsgCycleTime" BO_ 649 1000;
BA_ "GenSigStartValue" SG_ 649 HU_LocTiVld 1;
BA_ "GenMsgCycleTime" BO_ 654 100;
BA_ "GenMsgCycleTime" BO_ 656 100;
BA_ "GenMsgCycleTime" BO_ 657 200;
BA_ "GenSigStartValue" SG_ 657 iBCM_FL_TireP 255;
BA_ "GenSigStartValue" SG_ 657 iBCM_FR_TireP 255;
BA_ "GenSigStartValue" SG_ 657 iBCM_RL_TireP 255;
BA_ "GenSigStartValue" SG_ 657 iBCM_RR_TireP 255;
BA_ "GenMsgCycleTime" BO_ 658 200;
BA_ "GenSigStartValue" SG_ 658 iBCM_FL_TireTmp 255;
BA_ "GenSigStartValue" SG_ 658 iBCM_FR_TireTmp 255;
BA_ "GenSigStartValue" SG_ 658 iBCM_RL_TireTmp 255;
BA_ "GenSigStartValue" SG_ 658 iBCM_RR_TireTmp 255;
VAL_ 640 HU_ChrgMod 3 "Reserved" 2 "Reserved" 1 "Appoint Charging Mode" 0 "Normal Charging Mode" ;
VAL_ 640 HU_AppointChrgStartTi 63 "Invalid" 62 "Invalid" 61 "Invalid" 60 "Invalid" 59 "Invalid" 58 "Invalid" 57 "Invalid" 56 "Invalid" 55 "Invalid" 54 "Invalid" 53 "Invalid" 52 "Invalid" 51 "Invalid" 50 "Invalid" 49 "Invalid" 48 "Invalid" 47 "23:30" 46 "23:00" 45 "22:30" 44 "22:00" 43 "21:30" 42 "21:00" 41 "20:30" 40 "20:00" 39 "19:30" 38 "19:00" 37 "18:30" 36 "18:00" 35 "17:30" 34 "17:00" 33 "16:30" 32 "16:00" 31 "15:30" 30 "15:00" 29 "14:30" 28 "14:00" 27 "13:30" 26 "13:00" 25 "12:30" 24 "12:00" 23 "11:30" 22 "11:00" 21 "10:30" 20 "10:00" 19 "09:30" 18 "09:00" 17 "08:30" 16 "08:00" 15 "07:30" 14 "07:00" 13 "06:30" 12 "06:00" 11 "05:30" 10 "05:00" 9 "04:30" 8 "04:00" 7 "03:30" 6 "03:00" 5 "02:30" 4 "02:00" 3 "01:30" 2 "01:00" 1 "00:30" 0 "00:00" ;
VAL_ 640 HU_AppointChrgTi 31 "Invalid" 30 "Invalid" 29 "Invalid" 28 "Invalid" 27 "Invalid" 26 "Invalid" 25 "Invalid" 24 "Invalid" 23 "12 hour" 22 "11.5 hour" 21 "11 hour" 20 "10.5 hour" 19 "10 hour" 18 "9.5 hour" 17 "9 hour" 16 "8.5 hour" 15 "8 hour" 14 "7.5 hour" 13 "7 hour" 12 "6.5 hour" 11 "6 hour" 10 "5.5hour" 9 "5hour" 8 "4.5hour" 7 "4hour" 6 "3.5hour" 5 "3hour" 4 "2.5hour" 3 "2hour" 2 "1.5hour" 1 "1hour" 0 "0.5hour" ;
VAL_ 640 HU_CallHangUpSts 1 "Hang up" 0 "Call connection" ;
VAL_ 641 HU_TotlOdo 16777215 "Invalid" ;
VAL_ 649 HU_LocTiVld 1 "Validity" 0 "Invalidity" ;
VAL_ 649 HU_LocTiMth 15 "Invalid" 14 "Invalid" 13 "Invalid" 0 "Invalid" ;
VAL_ 649 HU_LocTiD 0 "Invalid" ;
VAL_ 649 HU_LocTiHr 31 "Invalid" 30 "Invalid" 29 "Invalid" 28 "Invalid" 27 "Invalid" 26 "Invalid" 25 "Invalid" 24 "Invalid" ;
VAL_ 649 HU_LocTiM 63 "Invalid" 62 "Invalid" 61 "Invalid" ;
VAL_ 649 HU_LocTiS 63 "Invalid" 62 "Invalid" 61 "Invalid" ;
VAL_ 1394 HU_RMR 1 "Rpt Msg state req" 0 "Rpt Msg state not req" ;
VAL_ 1394 HU_NMCodtrSleepBit 1 "Synch Shutdwn Req by codtr" 0 "Synch Shutdwn NotReq by codtr" ;
VAL_ 1394 HU_AWB 1 "Active wakeup" 0 "Passive wakeup" ;
VAL_ 1394 HU_PNI 1 "Contain PNI" 0 "Contain no PNI" ;
VAL_ 1395 AMP_RMR 1 "Rpt Msg state req" 0 "Rpt Msg state not req" ;
VAL_ 1395 AMP_NMCodtrSleepBit 1 "Synch Shutdwn Req by codtr" 0 "Synch Shutdwn NotReq by codtr" ;
VAL_ 1395 AMP_AWB 1 "Active wakeup" 0 "Passive wakeup" ;
VAL_ 1395 AMP_PNI 1 "Contain PNI" 0 "Contain no PNI" ;
VAL_ 1392 CGW_RMR 1 "Rpt Msg state req" 0 "Rpt Msg state not req" ;
VAL_ 1392 CGW_NMCodtrSleepBit 1 "Synch Shutdwn Req by codtr" 0 "Synch Shutdwn NotReq by codtr" ;
VAL_ 1392 CGW_AWB 1 "Active wakeup" 0 "Passive wakeup" ;
VAL_ 1392 CGW_PNI 1 "Contain PNI" 0 "Contain no PNI" ;
VAL_ 284 VCU_ChrgStsIndcr 1 "True" 0 "False" ;
VAL_ 284 VCU_ChrgConnectIndcr 1 "True" 0 "False" ;
VAL_ 285 VCU_VhclResidualMile 1023 "Invalid" 1022 "Invalid" 1021 "Invalid" 1020 "Invalid" 1019 "Invalid" 1018 "Invalid" 1017 "Invalid" 1016 "Invalid" 1015 "Invalid" 1014 "Invalid" 1013 "Invalid" 1012 "Invalid" 1011 "Invalid" 1010 "Invalid" 1009 "Invalid" 1008 "Invalid" 1007 "Invalid" 1006 "Invalid" 1005 "Invalid" 1004 "Invalid" 1003 "Invalid" 1002 "Invalid" 1001 "Invalid" 1000 "Invalid" 999 "Invalid" 998 "Invalid" 997 "Invalid" 996 "Invalid" 995 "Invalid" 994 "Invalid" 993 "Invalid" 992 "Invalid" 991 "Invalid" 990 "Invalid" 989 "Invalid" 988 "Invalid" 987 "Invalid" 986 "Invalid" 985 "Invalid" 984 "Invalid" 983 "Invalid" 982 "Invalid" 981 "Invalid" 980 "Invalid" 979 "Invalid" 978 "Invalid" 977 "Invalid" 976 "Invalid" 975 "Invalid" 974 "Invalid" 973 "Invalid" 972 "Invalid" 971 "Invalid" 970 "Invalid" 969 "Invalid" 968 "Invalid" 967 "Invalid" 966 "Invalid" 965 "Invalid" 964 "Invalid" 963 "Invalid" 962 "Invalid" 961 "Invalid" 960 "Invalid" 959 "Invalid" 958 "Invalid" 957 "Invalid" 956 "Invalid" 955 "Invalid" 954 "Invalid" 953 "Invalid" 952 "Invalid" 951 "Invalid" 950 "Invalid" 949 "Invalid" 948 "Invalid" 947 "Invalid" 946 "Invalid" 945 "Invalid" 944 "Invalid" 943 "Invalid" 942 "Invalid" 941 "Invalid" 940 "Invalid" 939 "Invalid" 938 "Invalid" 937 "Invalid" 936 "Invalid" 935 "Invalid" 934 "Invalid" 933 "Invalid" 932 "Invalid" 931 "Invalid" 930 "Invalid" 929 "Invalid" 928 "Invalid" 927 "Invalid" 926 "Invalid" 925 "Invalid" 924 "Invalid" 923 "Invalid" 922 "Invalid" 921 "Invalid" 920 "Invalid" 919 "Invalid" 918 "Invalid" 917 "Invalid" 916 "Invalid" 915 "Invalid" 914 "Invalid" 913 "Invalid" 912 "Invalid" 911 "Invalid" 910 "Invalid" 909 "Invalid" 908 "Invalid" 907 "Invalid" 906 "Invalid" 905 "Invalid" 904 "Invalid" 903 "Invalid" 902 "Invalid" 901 "Invalid" 900 "Invalid" 899 "Invalid" 898 "Invalid" 897 "Invalid" 896 "Invalid" 895 "Invalid" 894 "Invalid" 893 "Invalid" 892 "Invalid" 891 "Invalid" 890 "Invalid" 889 "Invalid" 888 "Invalid" 887 "Invalid" 886 "Invalid" 885 "Invalid" 884 "Invalid" 883 "Invalid" 882 "Invalid" 881 "Invalid" 880 "Invalid" 879 "Invalid" 878 "Invalid" 877 "Invalid" 876 "Invalid" 875 "Invalid" 874 "Invalid" 873 "Invalid" 872 "Invalid" 871 "Invalid" 870 "Invalid" 869 "Invalid" 868 "Invalid" 867 "Invalid" 866 "Invalid" 865 "Invalid" 864 "Invalid" 863 "Invalid" 862 "Invalid" 861 "Invalid" 860 "Invalid" 859 "Invalid" 858 "Invalid" 857 "Invalid" 856 "Invalid" 855 "Invalid" 854 "Invalid" 853 "Invalid" 852 "Invalid" 851 "Invalid" 850 "Invalid" 849 "Invalid" 848 "Invalid" 847 "Invalid" 846 "Invalid" 845 "Invalid" 844 "Invalid" 843 "Invalid" 842 "Invalid" 841 "Invalid" 840 "Invalid" 839 "Invalid" 838 "Invalid" 837 "Invalid" 836 "Invalid" 835 "Invalid" 834 "Invalid" 833 "Invalid" 832 "Invalid" 831 "Invalid" 830 "Invalid" 829 "Invalid" 828 "Invalid" 827 "Invalid" 826 "Invalid" 825 "Invalid" 824 "Invalid" 823 "Invalid" 822 "Invalid" 821 "Invalid" 820 "Invalid" 819 "Invalid" 818 "Invalid" 817 "Invalid" 816 "Invalid" 815 "Invalid" 814 "Invalid" 813 "Invalid" 812 "Invalid" 811 "Invalid" 810 "Invalid" 809 "Invalid" 808 "Invalid" 807 "Invalid" 806 "Invalid" 805 "Invalid" 804 "Invalid" 803 "Invalid" 802 "Invalid" 801 "Invalid" 800 "Invalid" 799 "Invalid" 798 "Invalid" 797 "Invalid" 796 "Invalid" 795 "Invalid" 794 "Invalid" 793 "Invalid" 792 "Invalid" 791 "Invalid" 790 "Invalid" 789 "Invalid" 788 "Invalid" 787 "Invalid" 786 "Invalid" 785 "Invalid" 784 "Invalid" 783 "Invalid" 782 "Invalid" 781 "Invalid" 780 "Invalid" 779 "Invalid" 778 "Invalid" 777 "Invalid" 776 "Invalid" 775 "Invalid" 774 "Invalid" 773 "Invalid" 772 "Invalid" 771 "Invalid" 770 "Invalid" 769 "Invalid" 768 "Invalid" 767 "Invalid" 766 "Invalid" 765 "Invalid" 764 "Invalid" 763 "Invalid" 762 "Invalid" 761 "Invalid" 760 "Invalid" 759 "Invalid" 758 "Invalid" 757 "Invalid" 756 "Invalid" 755 "Invalid" 754 "Invalid" 753 "Invalid" 752 "Invalid" 751 "Invalid" 750 "Invalid" 749 "Invalid" 748 "Invalid" 747 "Invalid" 746 "Invalid" 745 "Invalid" 744 "Invalid" 743 "Invalid" 742 "Invalid" 741 "Invalid" 740 "Invalid" 739 "Invalid" 738 "Invalid" 737 "Invalid" 736 "Invalid" 735 "Invalid" 734 "Invalid" 733 "Invalid" 732 "Invalid" 731 "Invalid" 730 "Invalid" 729 "Invalid" 728 "Invalid" 727 "Invalid" 726 "Invalid" 725 "Invalid" 724 "Invalid" 723 "Invalid" 722 "Invalid" 721 "Invalid" 720 "Invalid" 719 "Invalid" 718 "Invalid" 717 "Invalid" 716 "Invalid" 715 "Invalid" 714 "Invalid" 713 "Invalid" 712 "Invalid" 711 "Invalid" 710 "Invalid" 709 "Invalid" 708 "Invalid" 707 "Invalid" 706 "Invalid" 705 "Invalid" 704 "Invalid" 703 "Invalid" 702 "Invalid" 701 "Invalid" 700 "Invalid" 699 "Invalid" 698 "Invalid" 697 "Invalid" 696 "Invalid" 695 "Invalid" 694 "Invalid" 693 "Invalid" 692 "Invalid" 691 "Invalid" 690 "Invalid" 689 "Invalid" 688 "Invalid" 687 "Invalid" 686 "Invalid" 685 "Invalid" 684 "Invalid" 683 "Invalid" 682 "Invalid" 681 "Invalid" 680 "Invalid" 679 "Invalid" 678 "Invalid" 677 "Invalid" 676 "Invalid" 675 "Invalid" 674 "Invalid" 673 "Invalid" 672 "Invalid" 671 "Invalid" 670 "Invalid" 669 "Invalid" 668 "Invalid" 667 "Invalid" 666 "Invalid" 665 "Invalid" 664 "Invalid" 663 "Invalid" 662 "Invalid" 661 "Invalid" 660 "Invalid" 659 "Invalid" 658 "Invalid" 657 "Invalid" 656 "Invalid" 655 "Invalid" 654 "Invalid" 653 "Invalid" 652 "Invalid" 651 "Invalid" 650 "Invalid" 649 "Invalid" 648 "Invalid" 647 "Invalid" 646 "Invalid" 645 "Invalid" 644 "Invalid" 643 "Invalid" 642 "Invalid" 641 "Invalid" 640 "Invalid" 639 "Invalid" 638 "Invalid" 637 "Invalid" 636 "Invalid" 635 "Invalid" 634 "Invalid" 633 "Invalid" 632 "Invalid" 631 "Invalid" 630 "Invalid" 629 "Invalid" 628 "Invalid" 627 "Invalid" 626 "Invalid" 625 "Invalid" 624 "Invalid" 623 "Invalid" 622 "Invalid" 621 "Invalid" 620 "Invalid" 619 "Invalid" 618 "Invalid" 617 "Invalid" 616 "Invalid" 615 "Invalid" 614 "Invalid" 613 "Invalid" 612 "Invalid" 611 "Invalid" 610 "Invalid" 609 "Invalid" 608 "Invalid" 607 "Invalid" 606 "Invalid" 605 "Invalid" 604 "Invalid" 603 "Invalid" 602 "Invalid" 601 "Invalid" ;
VAL_ 370 VCU_AccrPedPosn 255 "Invalid" 254 "Invalid" 253 "Invalid" 252 "Invalid" 251 "Invalid" ;
VAL_ 370 VCU_AccrPedPosnVld 1 "Validity" 0 "Invalidity" ;
VAL_ 370 VCU_ActlGear 7 "Reserved" 6 "Reserved" 5 "Reserved" 4 "Reserved" 3 "D" 2 "N" 1 "R" 0 "P" ;
VAL_ 370 VCU_PtRdy 1 "True" 0 "False" ;
VAL_ 370 VCU_SchChrgStopRsn 7 "Reserved" 6 "Crash happened" 5 "Charging gun not plug in" 4 "220V not connect(CC but no CP)" 3 "Normal stop" 2 "PT system fault stop" 1 "Charging full stop" 0 "Default" ;
VAL_ 370 VCU_WakeUpByCPDurgSchChrg 1 "VCU wakeup by CP" 0 "VCU not wakeup by CP" ;
VAL_ 371 VCU_CPConctSts 7 "Reserved" 6 "Reserved" 5 "Reserved" 4 "CP sigl failure" 3 "Conct and allowed chrg" 2 "Conct but chrg not allowed" 1 "S2 locked up state failure" 0 "Not connect" ;
VAL_ 371 VCU_CCConctSts 3 "Reserved" 2 "Error" 1 "Connect" 0 "Not connect" ;
VAL_ 371 VCU_VhclFltLvl 7 "Level Ⅶ" 6 "Level Ⅵ" 5 "Level Ⅴ" 4 "Level Ⅳ" 3 "Level Ⅲ" 2 "Level Ⅱ" 1 "Level Ⅰ" 0 "No Error" ;
VAL_ 371 VCU_DrvgMotNr_RM 3 "Front motor driving(Number 3)" 2 "Both motor driving(Number 2)" 1 "Rear motor driving(Number 1)" 0 "No driving" ;
VAL_ 792 MCU_MotActlTq_RM_Frnt 2047 "Invalid" 2046 "Invalid" 2045 "Invalid" 2044 "Invalid" 2043 "Invalid" 2042 "Invalid" 2041 "Invalid" 2040 "Invalid" 2039 "Invalid" 2038 "Invalid" 2037 "Invalid" 2036 "Invalid" 2035 "Invalid" 2034 "Invalid" 2033 "Invalid" 2032 "Invalid" 2031 "Invalid" 2030 "Invalid" 2029 "Invalid" 2028 "Invalid" 2027 "Invalid" 2026 "Invalid" 2025 "Invalid" 2024 "Invalid" 2023 "Invalid" 2022 "Invalid" 2021 "Invalid" 2020 "Invalid" 2019 "Invalid" 2018 "Invalid" 2017 "Invalid" 2016 "Invalid" 2015 "Invalid" 2014 "Invalid" 2013 "Invalid" 2012 "Invalid" 2011 "Invalid" 2010 "Invalid" 2009 "Invalid" 2008 "Invalid" 2007 "Invalid" 2006 "Invalid" 2005 "Invalid" 2004 "Invalid" 2003 "Invalid" 2002 "Invalid" 2001 "Invalid" ;
VAL_ 792 MCU_MotActlTmp_RM_Frnt 255 "Invalid" ;
VAL_ 792 MCU_ActTmp_RM_Frnt 255 "Invalid" ;
VAL_ 529 BCU_SOCAppl 1023 "Invalid" 1022 "Invalid" 1021 "Invalid" 1020 "Invalid" 1019 "Invalid" 1018 "Invalid" 1017 "Invalid" 1016 "Invalid" 1015 "Invalid" 1014 "Invalid" 1013 "Invalid" 1012 "Invalid" 1011 "Invalid" 1010 "Invalid" 1009 "Invalid" 1008 "Invalid" 1007 "Invalid" 1006 "Invalid" 1005 "Invalid" 1004 "Invalid" 1003 "Invalid" 1002 "Invalid" 1001 "Invalid" ;
VAL_ 529 BCU_BattVlt 8191 "Invalid" 8190 "Invalid" 8189 "Invalid" 8188 "Invalid" 8187 "Invalid" 8186 "Invalid" 8185 "Invalid" 8184 "Invalid" 8183 "Invalid" 8182 "Invalid" 8181 "Invalid" 8180 "Invalid" 8179 "Invalid" 8178 "Invalid" 8177 "Invalid" 8176 "Invalid" 8175 "Invalid" 8174 "Invalid" 8173 "Invalid" 8172 "Invalid" 8171 "Invalid" 8170 "Invalid" 8169 "Invalid" 8168 "Invalid" 8167 "Invalid" 8166 "Invalid" 8165 "Invalid" 8164 "Invalid" 8163 "Invalid" 8162 "Invalid" 8161 "Invalid" 8160 "Invalid" 8159 "Invalid" 8158 "Invalid" 8157 "Invalid" 8156 "Invalid" 8155 "Invalid" 8154 "Invalid" 8153 "Invalid" 8152 "Invalid" 8151 "Invalid" 8150 "Invalid" 8149 "Invalid" 8148 "Invalid" 8147 "Invalid" 8146 "Invalid" 8145 "Invalid" 8144 "Invalid" 8143 "Invalid" 8142 "Invalid" 8141 "Invalid" 8140 "Invalid" 8139 "Invalid" 8138 "Invalid" 8137 "Invalid" 8136 "Invalid" 8135 "Invalid" 8134 "Invalid" 8133 "Invalid" 8132 "Invalid" 8131 "Invalid" 8130 "Invalid" 8129 "Invalid" 8128 "Invalid" 8127 "Invalid" 8126 "Invalid" 8125 "Invalid" 8124 "Invalid" 8123 "Invalid" 8122 "Invalid" 8121 "Invalid" 8120 "Invalid" 8119 "Invalid" 8118 "Invalid" 8117 "Invalid" 8116 "Invalid" 8115 "Invalid" 8114 "Invalid" 8113 "Invalid" 8112 "Invalid" 8111 "Invalid" 8110 "Invalid" 8109 "Invalid" 8108 "Invalid" 8107 "Invalid" 8106 "Invalid" 8105 "Invalid" 8104 "Invalid" 8103 "Invalid" 8102 "Invalid" 8101 "Invalid" 8100 "Invalid" 8099 "Invalid" 8098 "Invalid" 8097 "Invalid" 8096 "Invalid" 8095 "Invalid" 8094 "Invalid" 8093 "Invalid" 8092 "Invalid" 8091 "Invalid" 8090 "Invalid" 8089 "Invalid" 8088 "Invalid" 8087 "Invalid" 8086 "Invalid" 8085 "Invalid" 8084 "Invalid" 8083 "Invalid" 8082 "Invalid" 8081 "Invalid" 8080 "Invalid" 8079 "Invalid" 8078 "Invalid" 8077 "Invalid" 8076 "Invalid" 8075 "Invalid" 8074 "Invalid" 8073 "Invalid" 8072 "Invalid" 8071 "Invalid" 8070 "Invalid" 8069 "Invalid" 8068 "Invalid" 8067 "Invalid" 8066 "Invalid" 8065 "Invalid" 8064 "Invalid" 8063 "Invalid" 8062 "Invalid" 8061 "Invalid" 8060 "Invalid" 8059 "Invalid" 8058 "Invalid" 8057 "Invalid" 8056 "Invalid" 8055 "Invalid" 8054 "Invalid" 8053 "Invalid" 8052 "Invalid" 8051 "Invalid" 8050 "Invalid" 8049 "Invalid" 8048 "Invalid" 8047 "Invalid" 8046 "Invalid" 8045 "Invalid" 8044 "Invalid" 8043 "Invalid" 8042 "Invalid" 8041 "Invalid" 8040 "Invalid" 8039 "Invalid" 8038 "Invalid" 8037 "Invalid" 8036 "Invalid" 8035 "Invalid" 8034 "Invalid" 8033 "Invalid" 8032 "Invalid" 8031 "Invalid" 8030 "Invalid" 8029 "Invalid" 8028 "Invalid" 8027 "Invalid" 8026 "Invalid" 8025 "Invalid" 8024 "Invalid" 8023 "Invalid" 8022 "Invalid" 8021 "Invalid" 8020 "Invalid" 8019 "Invalid" 8018 "Invalid" 8017 "Invalid" 8016 "Invalid" 8015 "Invalid" 8014 "Invalid" 8013 "Invalid" 8012 "Invalid" 8011 "Invalid" 8010 "Invalid" 8009 "Invalid" 8008 "Invalid" 8007 "Invalid" 8006 "Invalid" 8005 "Invalid" 8004 "Invalid" 8003 "Invalid" 8002 "Invalid" 8001 "Invalid" 8000 "Invalid" 7999 "Invalid" 7998 "Invalid" 7997 "Invalid" 7996 "Invalid" 7995 "Invalid" 7994 "Invalid" 7993 "Invalid" 7992 "Invalid" 7991 "Invalid" 7990 "Invalid" 7989 "Invalid" 7988 "Invalid" 7987 "Invalid" 7986 "Invalid" 7985 "Invalid" 7984 "Invalid" 7983 "Invalid" 7982 "Invalid" 7981 "Invalid" 7980 "Invalid" 7979 "Invalid" 7978 "Invalid" 7977 "Invalid" 7976 "Invalid" 7975 "Invalid" 7974 "Invalid" 7973 "Invalid" 7972 "Invalid" 7971 "Invalid" 7970 "Invalid" 7969 "Invalid" 7968 "Invalid" 7967 "Invalid" 7966 "Invalid" 7965 "Invalid" 7964 "Invalid" 7963 "Invalid" 7962 "Invalid" 7961 "Invalid" 7960 "Invalid" 7959 "Invalid" 7958 "Invalid" 7957 "Invalid" 7956 "Invalid" 7955 "Invalid" 7954 "Invalid" 7953 "Invalid" 7952 "Invalid" 7951 "Invalid" 7950 "Invalid" 7949 "Invalid" 7948 "Invalid" 7947 "Invalid" 7946 "Invalid" 7945 "Invalid" 7944 "Invalid" 7943 "Invalid" 7942 "Invalid" 7941 "Invalid" 7940 "Invalid" 7939 "Invalid" 7938 "Invalid" 7937 "Invalid" 7936 "Invalid" 7935 "Invalid" 7934 "Invalid" 7933 "Invalid" 7932 "Invalid" 7931 "Invalid" 7930 "Invalid" 7929 "Invalid" 7928 "Invalid" 7927 "Invalid" 7926 "Invalid" 7925 "Invalid" 7924 "Invalid" 7923 "Invalid" 7922 "Invalid" 7921 "Invalid" 7920 "Invalid" 7919 "Invalid" 7918 "Invalid" 7917 "Invalid" 7916 "Invalid" 7915 "Invalid" 7914 "Invalid" 7913 "Invalid" 7912 "Invalid" 7911 "Invalid" 7910 "Invalid" 7909 "Invalid" 7908 "Invalid" 7907 "Invalid" 7906 "Invalid" 7905 "Invalid" 7904 "Invalid" 7903 "Invalid" 7902 "Invalid" 7901 "Invalid" 7900 "Invalid" 7899 "Invalid" 7898 "Invalid" 7897 "Invalid" 7896 "Invalid" 7895 "Invalid" 7894 "Invalid" 7893 "Invalid" 7892 "Invalid" 7891 "Invalid" 7890 "Invalid" 7889 "Invalid" 7888 "Invalid" 7887 "Invalid" 7886 "Invalid" 7885 "Invalid" 7884 "Invalid" 7883 "Invalid" 7882 "Invalid" 7881 "Invalid" 7880 "Invalid" 7879 "Invalid" 7878 "Invalid" 7877 "Invalid" 7876 "Invalid" 7875 "Invalid" 7874 "Invalid" 7873 "Invalid" 7872 "Invalid" 7871 "Invalid" 7870 "Invalid" 7869 "Invalid" 7868 "Invalid" 7867 "Invalid" 7866 "Invalid" 7865 "Invalid" 7864 "Invalid" 7863 "Invalid" 7862 "Invalid" 7861 "Invalid" 7860 "Invalid" 7859 "Invalid" 7858 "Invalid" 7857 "Invalid" 7856 "Invalid" 7855 "Invalid" 7854 "Invalid" 7853 "Invalid" 7852 "Invalid" 7851 "Invalid" 7850 "Invalid" 7849 "Invalid" 7848 "Invalid" 7847 "Invalid" 7846 "Invalid" 7845 "Invalid" 7844 "Invalid" 7843 "Invalid" 7842 "Invalid" 7841 "Invalid" 7840 "Invalid" 7839 "Invalid" 7838 "Invalid" 7837 "Invalid" 7836 "Invalid" 7835 "Invalid" 7834 "Invalid" 7833 "Invalid" 7832 "Invalid" 7831 "Invalid" 7830 "Invalid" 7829 "Invalid" 7828 "Invalid" 7827 "Invalid" 7826 "Invalid" 7825 "Invalid" 7824 "Invalid" 7823 "Invalid" 7822 "Invalid" 7821 "Invalid" 7820 "Invalid" 7819 "Invalid" 7818 "Invalid" 7817 "Invalid" 7816 "Invalid" 7815 "Invalid" 7814 "Invalid" 7813 "Invalid" 7812 "Invalid" 7811 "Invalid" 7810 "Invalid" 7809 "Invalid" 7808 "Invalid" 7807 "Invalid" 7806 "Invalid" 7805 "Invalid" 7804 "Invalid" 7803 "Invalid" 7802 "Invalid" 7801 "Invalid" 7800 "Invalid" 7799 "Invalid" 7798 "Invalid" 7797 "Invalid" 7796 "Invalid" 7795 "Invalid" 7794 "Invalid" 7793 "Invalid" 7792 "Invalid" 7791 "Invalid" 7790 "Invalid" 7789 "Invalid" 7788 "Invalid" 7787 "Invalid" 7786 "Invalid" 7785 "Invalid" 7784 "Invalid" 7783 "Invalid" 7782 "Invalid" 7781 "Invalid" 7780 "Invalid" 7779 "Invalid" 7778 "Invalid" 7777 "Invalid" 7776 "Invalid" 7775 "Invalid" 7774 "Invalid" 7773 "Invalid" 7772 "Invalid" 7771 "Invalid" 7770 "Invalid" 7769 "Invalid" 7768 "Invalid" 7767 "Invalid" 7766 "Invalid" 7765 "Invalid" 7764 "Invalid" 7763 "Invalid" 7762 "Invalid" 7761 "Invalid" 7760 "Invalid" 7759 "Invalid" 7758 "Invalid" 7757 "Invalid" 7756 "Invalid" 7755 "Invalid" 7754 "Invalid" 7753 "Invalid" 7752 "Invalid" 7751 "Invalid" 7750 "Invalid" 7749 "Invalid" 7748 "Invalid" 7747 "Invalid" 7746 "Invalid" 7745 "Invalid" 7744 "Invalid" 7743 "Invalid" 7742 "Invalid" 7741 "Invalid" 7740 "Invalid" 7739 "Invalid" 7738 "Invalid" 7737 "Invalid" 7736 "Invalid" 7735 "Invalid" 7734 "Invalid" 7733 "Invalid" 7732 "Invalid" 7731 "Invalid" 7730 "Invalid" 7729 "Invalid" 7728 "Invalid" 7727 "Invalid" 7726 "Invalid" 7725 "Invalid" 7724 "Invalid" 7723 "Invalid" 7722 "Invalid" 7721 "Invalid" 7720 "Invalid" 7719 "Invalid" 7718 "Invalid" 7717 "Invalid" 7716 "Invalid" 7715 "Invalid" 7714 "Invalid" 7713 "Invalid" 7712 "Invalid" 7711 "Invalid" 7710 "Invalid" 7709 "Invalid" 7708 "Invalid" 7707 "Invalid" 7706 "Invalid" 7705 "Invalid" 7704 "Invalid" 7703 "Invalid" 7702 "Invalid" 7701 "Invalid" 7700 "Invalid" 7699 "Invalid" 7698 "Invalid" 7697 "Invalid" 7696 "Invalid" 7695 "Invalid" 7694 "Invalid" 7693 "Invalid" 7692 "Invalid" 7691 "Invalid" 7690 "Invalid" 7689 "Invalid" 7688 "Invalid" 7687 "Invalid" 7686 "Invalid" 7685 "Invalid" 7684 "Invalid" 7683 "Invalid" 7682 "Invalid" 7681 "Invalid" 7680 "Invalid" 7679 "Invalid" 7678 "Invalid" 7677 "Invalid" 7676 "Invalid" 7675 "Invalid" 7674 "Invalid" 7673 "Invalid" 7672 "Invalid" 7671 "Invalid" 7670 "Invalid" 7669 "Invalid" 7668 "Invalid" 7667 "Invalid" 7666 "Invalid" 7665 "Invalid" 7664 "Invalid" 7663 "Invalid" 7662 "Invalid" 7661 "Invalid" 7660 "Invalid" 7659 "Invalid" 7658 "Invalid" 7657 "Invalid" 7656 "Invalid" 7655 "Invalid" 7654 "Invalid" 7653 "Invalid" 7652 "Invalid" 7651 "Invalid" 7650 "Invalid" 7649 "Invalid" 7648 "Invalid" 7647 "Invalid" 7646 "Invalid" 7645 "Invalid" 7644 "Invalid" 7643 "Invalid" 7642 "Invalid" 7641 "Invalid" 7640 "Invalid" 7639 "Invalid" 7638 "Invalid" 7637 "Invalid" 7636 "Invalid" 7635 "Invalid" 7634 "Invalid" 7633 "Invalid" 7632 "Invalid" 7631 "Invalid" 7630 "Invalid" 7629 "Invalid" 7628 "Invalid" 7627 "Invalid" 7626 "Invalid" 7625 "Invalid" 7624 "Invalid" 7623 "Invalid" 7622 "Invalid" 7621 "Invalid" 7620 "Invalid" 7619 "Invalid" 7618 "Invalid" 7617 "Invalid" 7616 "Invalid" 7615 "Invalid" 7614 "Invalid" 7613 "Invalid" 7612 "Invalid" 7611 "Invalid" 7610 "Invalid" 7609 "Invalid" 7608 "Invalid" 7607 "Invalid" 7606 "Invalid" 7605 "Invalid" 7604 "Invalid" 7603 "Invalid" 7602 "Invalid" 7601 "Invalid" 7600 "Invalid" 7599 "Invalid" 7598 "Invalid" 7597 "Invalid" 7596 "Invalid" 7595 "Invalid" 7594 "Invalid" 7593 "Invalid" 7592 "Invalid" 7591 "Invalid" 7590 "Invalid" 7589 "Invalid" 7588 "Invalid" 7587 "Invalid" 7586 "Invalid" 7585 "Invalid" 7584 "Invalid" 7583 "Invalid" 7582 "Invalid" 7581 "Invalid" 7580 "Invalid" 7579 "Invalid" 7578 "Invalid" 7577 "Invalid" 7576 "Invalid" 7575 "Invalid" 7574 "Invalid" 7573 "Invalid" 7572 "Invalid" 7571 "Invalid" 7570 "Invalid" 7569 "Invalid" 7568 "Invalid" 7567 "Invalid" 7566 "Invalid" 7565 "Invalid" 7564 "Invalid" 7563 "Invalid" 7562 "Invalid" 7561 "Invalid" 7560 "Invalid" 7559 "Invalid" 7558 "Invalid" 7557 "Invalid" 7556 "Invalid" 7555 "Invalid" 7554 "Invalid" 7553 "Invalid" 7552 "Invalid" 7551 "Invalid" 7550 "Invalid" 7549 "Invalid" 7548 "Invalid" 7547 "Invalid" 7546 "Invalid" 7545 "Invalid" 7544 "Invalid" 7543 "Invalid" 7542 "Invalid" 7541 "Invalid" 7540 "Invalid" 7539 "Invalid" 7538 "Invalid" 7537 "Invalid" 7536 "Invalid" 7535 "Invalid" 7534 "Invalid" 7533 "Invalid" 7532 "Invalid" 7531 "Invalid" 7530 "Invalid" 7529 "Invalid" 7528 "Invalid" 7527 "Invalid" 7526 "Invalid" 7525 "Invalid" 7524 "Invalid" 7523 "Invalid" 7522 "Invalid" 7521 "Invalid" 7520 "Invalid" 7519 "Invalid" 7518 "Invalid" 7517 "Invalid" 7516 "Invalid" 7515 "Invalid" 7514 "Invalid" 7513 "Invalid" 7512 "Invalid" 7511 "Invalid" 7510 "Invalid" 7509 "Invalid" 7508 "Invalid" 7507 "Invalid" 7506 "Invalid" 7505 "Invalid" 7504 "Invalid" 7503 "Invalid" 7502 "Invalid" 7501 "Invalid" 7500 "Invalid" 7499 "Invalid" 7498 "Invalid" 7497 "Invalid" 7496 "Invalid" 7495 "Invalid" 7494 "Invalid" 7493 "Invalid" 7492 "Invalid" 7491 "Invalid" 7490 "Invalid" 7489 "Invalid" 7488 "Invalid" 7487 "Invalid" 7486 "Invalid" 7485 "Invalid" 7484 "Invalid" 7483 "Invalid" 7482 "Invalid" 7481 "Invalid" 7480 "Invalid" 7479 "Invalid" 7478 "Invalid" 7477 "Invalid" 7476 "Invalid" 7475 "Invalid" 7474 "Invalid" 7473 "Invalid" 7472 "Invalid" 7471 "Invalid" 7470 "Invalid" 7469 "Invalid" 7468 "Invalid" 7467 "Invalid" 7466 "Invalid" 7465 "Invalid" 7464 "Invalid" 7463 "Invalid" 7462 "Invalid" 7461 "Invalid" 7460 "Invalid" 7459 "Invalid" 7458 "Invalid" 7457 "Invalid" 7456 "Invalid" 7455 "Invalid" 7454 "Invalid" 7453 "Invalid" 7452 "Invalid" 7451 "Invalid" 7450 "Invalid" 7449 "Invalid" 7448 "Invalid" 7447 "Invalid" 7446 "Invalid" 7445 "Invalid" 7444 "Invalid" 7443 "Invalid" 7442 "Invalid" 7441 "Invalid" 7440 "Invalid" 7439 "Invalid" 7438 "Invalid" 7437 "Invalid" 7436 "Invalid" 7435 "Invalid" 7434 "Invalid" 7433 "Invalid" 7432 "Invalid" 7431 "Invalid" 7430 "Invalid" 7429 "Invalid" 7428 "Invalid" 7427 "Invalid" 7426 "Invalid" 7425 "Invalid" 7424 "Invalid" 7423 "Invalid" 7422 "Invalid" 7421 "Invalid" 7420 "Invalid" 7419 "Invalid" 7418 "Invalid" 7417 "Invalid" 7416 "Invalid" 7415 "Invalid" 7414 "Invalid" 7413 "Invalid" 7412 "Invalid" 7411 "Invalid" 7410 "Invalid" 7409 "Invalid" 7408 "Invalid" 7407 "Invalid" 7406 "Invalid" 7405 "Invalid" 7404 "Invalid" 7403 "Invalid" 7402 "Invalid" 7401 "Invalid" 7400 "Invalid" 7399 "Invalid" 7398 "Invalid" 7397 "Invalid" 7396 "Invalid" 7395 "Invalid" 7394 "Invalid" 7393 "Invalid" 7392 "Invalid" 7391 "Invalid" 7390 "Invalid" 7389 "Invalid" 7388 "Invalid" 7387 "Invalid" 7386 "Invalid" 7385 "Invalid" 7384 "Invalid" 7383 "Invalid" 7382 "Invalid" 7381 "Invalid" 7380 "Invalid" 7379 "Invalid" 7378 "Invalid" 7377 "Invalid" 7376 "Invalid" 7375 "Invalid" 7374 "Invalid" 7373 "Invalid" 7372 "Invalid" 7371 "Invalid" 7370 "Invalid" 7369 "Invalid" 7368 "Invalid" 7367 "Invalid" 7366 "Invalid" 7365 "Invalid" 7364 "Invalid" 7363 "Invalid" 7362 "Invalid" 7361 "Invalid" 7360 "Invalid" 7359 "Invalid" 7358 "Invalid" 7357 "Invalid" 7356 "Invalid" 7355 "Invalid" 7354 "Invalid" 7353 "Invalid" 7352 "Invalid" 7351 "Invalid" 7350 "Invalid" 7349 "Invalid" 7348 "Invalid" 7347 "Invalid" 7346 "Invalid" 7345 "Invalid" 7344 "Invalid" 7343 "Invalid" 7342 "Invalid" 7341 "Invalid" 7340 "Invalid" 7339 "Invalid" 7338 "Invalid" 7337 "Invalid" 7336 "Invalid" 7335 "Invalid" 7334 "Invalid" 7333 "Invalid" 7332 "Invalid" 7331 "Invalid" 7330 "Invalid" 7329 "Invalid" 7328 "Invalid" 7327 "Invalid" 7326 "Invalid" 7325 "Invalid" 7324 "Invalid" 7323 "Invalid" 7322 "Invalid" 7321 "Invalid" 7320 "Invalid" 7319 "Invalid" 7318 "Invalid" 7317 "Invalid" 7316 "Invalid" 7315 "Invalid" 7314 "Invalid" 7313 "Invalid" 7312 "Invalid" 7311 "Invalid" 7310 "Invalid" 7309 "Invalid" 7308 "Invalid" 7307 "Invalid" 7306 "Invalid" 7305 "Invalid" 7304 "Invalid" 7303 "Invalid" 7302 "Invalid" 7301 "Invalid" 7300 "Invalid" 7299 "Invalid" 7298 "Invalid" 7297 "Invalid" 7296 "Invalid" 7295 "Invalid" 7294 "Invalid" 7293 "Invalid" 7292 "Invalid" 7291 "Invalid" 7290 "Invalid" 7289 "Invalid" 7288 "Invalid" 7287 "Invalid" 7286 "Invalid" 7285 "Invalid" 7284 "Invalid" 7283 "Invalid" 7282 "Invalid" 7281 "Invalid" 7280 "Invalid" 7279 "Invalid" 7278 "Invalid" 7277 "Invalid" 7276 "Invalid" 7275 "Invalid" 7274 "Invalid" 7273 "Invalid" 7272 "Invalid" 7271 "Invalid" 7270 "Invalid" 7269 "Invalid" 7268 "Invalid" 7267 "Invalid" 7266 "Invalid" 7265 "Invalid" 7264 "Invalid" 7263 "Invalid" 7262 "Invalid" 7261 "Invalid" 7260 "Invalid" 7259 "Invalid" 7258 "Invalid" 7257 "Invalid" 7256 "Invalid" 7255 "Invalid" 7254 "Invalid" 7253 "Invalid" 7252 "Invalid" 7251 "Invalid" 7250 "Invalid" 7249 "Invalid" 7248 "Invalid" 7247 "Invalid" 7246 "Invalid" 7245 "Invalid" 7244 "Invalid" 7243 "Invalid" 7242 "Invalid" 7241 "Invalid" 7240 "Invalid" 7239 "Invalid" 7238 "Invalid" 7237 "Invalid" 7236 "Invalid" 7235 "Invalid" 7234 "Invalid" 7233 "Invalid" 7232 "Invalid" 7231 "Invalid" 7230 "Invalid" 7229 "Invalid" 7228 "Invalid" 7227 "Invalid" 7226 "Invalid" 7225 "Invalid" 7224 "Invalid" 7223 "Invalid" 7222 "Invalid" 7221 "Invalid" 7220 "Invalid" 7219 "Invalid" 7218 "Invalid" 7217 "Invalid" 7216 "Invalid" 7215 "Invalid" 7214 "Invalid" 7213 "Invalid" 7212 "Invalid" 7211 "Invalid" 7210 "Invalid" 7209 "Invalid" 7208 "Invalid" 7207 "Invalid" 7206 "Invalid" 7205 "Invalid" 7204 "Invalid" 7203 "Invalid" 7202 "Invalid" 7201 "Invalid" 7200 "Invalid" 7199 "Invalid" 7198 "Invalid" 7197 "Invalid" 7196 "Invalid" 7195 "Invalid" 7194 "Invalid" 7193 "Invalid" 7192 "Invalid" 7191 "Invalid" 7190 "Invalid" 7189 "Invalid" 7188 "Invalid" 7187 "Invalid" 7186 "Invalid" 7185 "Invalid" 7184 "Invalid" 7183 "Invalid" 7182 "Invalid" 7181 "Invalid" 7180 "Invalid" 7179 "Invalid" 7178 "Invalid" 7177 "Invalid" 7176 "Invalid" 7175 "Invalid" 7174 "Invalid" 7173 "Invalid" 7172 "Invalid" 7171 "Invalid" 7170 "Invalid" 7169 "Invalid" 7168 "Invalid" 7167 "Invalid" 7166 "Invalid" 7165 "Invalid" 7164 "Invalid" 7163 "Invalid" 7162 "Invalid" 7161 "Invalid" 7160 "Invalid" 7159 "Invalid" 7158 "Invalid" 7157 "Invalid" 7156 "Invalid" 7155 "Invalid" 7154 "Invalid" 7153 "Invalid" 7152 "Invalid" 7151 "Invalid" 7150 "Invalid" 7149 "Invalid" 7148 "Invalid" 7147 "Invalid" 7146 "Invalid" 7145 "Invalid" 7144 "Invalid" 7143 "Invalid" 7142 "Invalid" 7141 "Invalid" 7140 "Invalid" 7139 "Invalid" 7138 "Invalid" 7137 "Invalid" 7136 "Invalid" 7135 "Invalid" 7134 "Invalid" 7133 "Invalid" 7132 "Invalid" 7131 "Invalid" 7130 "Invalid" 7129 "Invalid" 7128 "Invalid" 7127 "Invalid" 7126 "Invalid" 7125 "Invalid" 7124 "Invalid" 7123 "Invalid" 7122 "Invalid" 7121 "Invalid" 7120 "Invalid" 7119 "Invalid" 7118 "Invalid" 7117 "Invalid" 7116 "Invalid" 7115 "Invalid" 7114 "Invalid" 7113 "Invalid" 7112 "Invalid" 7111 "Invalid" 7110 "Invalid" 7109 "Invalid" 7108 "Invalid" 7107 "Invalid" 7106 "Invalid" 7105 "Invalid" 7104 "Invalid" 7103 "Invalid" 7102 "Invalid" 7101 "Invalid" 7100 "Invalid" 7099 "Invalid" 7098 "Invalid" 7097 "Invalid" 7096 "Invalid" 7095 "Invalid" 7094 "Invalid" 7093 "Invalid" 7092 "Invalid" 7091 "Invalid" 7090 "Invalid" 7089 "Invalid" 7088 "Invalid" 7087 "Invalid" 7086 "Invalid" 7085 "Invalid" 7084 "Invalid" 7083 "Invalid" 7082 "Invalid" 7081 "Invalid" 7080 "Invalid" 7079 "Invalid" 7078 "Invalid" 7077 "Invalid" 7076 "Invalid" 7075 "Invalid" 7074 "Invalid" 7073 "Invalid" 7072 "Invalid" 7071 "Invalid" 7070 "Invalid" 7069 "Invalid" 7068 "Invalid" 7067 "Invalid" 7066 "Invalid" 7065 "Invalid" 7064 "Invalid" 7063 "Invalid" 7062 "Invalid" 7061 "Invalid" 7060 "Invalid" 7059 "Invalid" 7058 "Invalid" 7057 "Invalid" 7056 "Invalid" 7055 "Invalid" 7054 "Invalid" 7053 "Invalid" 7052 "Invalid" 7051 "Invalid" 7050 "Invalid" 7049 "Invalid" 7048 "Invalid" 7047 "Invalid" 7046 "Invalid" 7045 "Invalid" 7044 "Invalid" 7043 "Invalid" 7042 "Invalid" 7041 "Invalid" 7040 "Invalid" 7039 "Invalid" 7038 "Invalid" 7037 "Invalid" 7036 "Invalid" 7035 "Invalid" 7034 "Invalid" 7033 "Invalid" 7032 "Invalid" 7031 "Invalid" 7030 "Invalid" 7029 "Invalid" 7028 "Invalid" 7027 "Invalid" 7026 "Invalid" 7025 "Invalid" 7024 "Invalid" 7023 "Invalid" 7022 "Invalid" 7021 "Invalid" 7020 "Invalid" 7019 "Invalid" 7018 "Invalid" 7017 "Invalid" 7016 "Invalid" 7015 "Invalid" 7014 "Invalid" 7013 "Invalid" 7012 "Invalid" 7011 "Invalid" 7010 "Invalid" 7009 "Invalid" 7008 "Invalid" 7007 "Invalid" 7006 "Invalid" 7005 "Invalid" 7004 "Invalid" 7003 "Invalid" 7002 "Invalid" 7001 "Invalid" 7000 "Invalid" 6999 "Invalid" 6998 "Invalid" 6997 "Invalid" 6996 "Invalid" 6995 "Invalid" 6994 "Invalid" 6993 "Invalid" 6992 "Invalid" 6991 "Invalid" 6990 "Invalid" 6989 "Invalid" 6988 "Invalid" 6987 "Invalid" 6986 "Invalid" 6985 "Invalid" 6984 "Invalid" 6983 "Invalid" 6982 "Invalid" 6981 "Invalid" 6980 "Invalid" 6979 "Invalid" 6978 "Invalid" 6977 "Invalid" 6976 "Invalid" 6975 "Invalid" 6974 "Invalid" 6973 "Invalid" 6972 "Invalid" 6971 "Invalid" 6970 "Invalid" 6969 "Invalid" 6968 "Invalid" 6967 "Invalid" 6966 "Invalid" 6965 "Invalid" 6964 "Invalid" 6963 "Invalid" 6962 "Invalid" 6961 "Invalid" 6960 "Invalid" 6959 "Invalid" 6958 "Invalid" 6957 "Invalid" 6956 "Invalid" 6955 "Invalid" 6954 "Invalid" 6953 "Invalid" 6952 "Invalid" 6951 "Invalid" 6950 "Invalid" 6949 "Invalid" 6948 "Invalid" 6947 "Invalid" 6946 "Invalid" 6945 "Invalid" 6944 "Invalid" 6943 "Invalid" 6942 "Invalid" 6941 "Invalid" 6940 "Invalid" 6939 "Invalid" 6938 "Invalid" 6937 "Invalid" 6936 "Invalid" 6935 "Invalid" 6934 "Invalid" 6933 "Invalid" 6932 "Invalid" 6931 "Invalid" 6930 "Invalid" 6929 "Invalid" 6928 "Invalid" 6927 "Invalid" 6926 "Invalid" 6925 "Invalid" 6924 "Invalid" 6923 "Invalid" 6922 "Invalid" 6921 "Invalid" 6920 "Invalid" 6919 "Invalid" 6918 "Invalid" 6917 "Invalid" 6916 "Invalid" 6915 "Invalid" 6914 "Invalid" 6913 "Invalid" 6912 "Invalid" 6911 "Invalid" 6910 "Invalid" 6909 "Invalid" 6908 "Invalid" 6907 "Invalid" 6906 "Invalid" 6905 "Invalid" 6904 "Invalid" 6903 "Invalid" 6902 "Invalid" 6901 "Invalid" 6900 "Invalid" 6899 "Invalid" 6898 "Invalid" 6897 "Invalid" 6896 "Invalid" 6895 "Invalid" 6894 "Invalid" 6893 "Invalid" 6892 "Invalid" 6891 "Invalid" 6890 "Invalid" 6889 "Invalid" 6888 "Invalid" 6887 "Invalid" 6886 "Invalid" 6885 "Invalid" 6884 "Invalid" 6883 "Invalid" 6882 "Invalid" 6881 "Invalid" 6880 "Invalid" 6879 "Invalid" 6878 "Invalid" 6877 "Invalid" 6876 "Invalid" 6875 "Invalid" 6874 "Invalid" 6873 "Invalid" 6872 "Invalid" 6871 "Invalid" 6870 "Invalid" 6869 "Invalid" 6868 "Invalid" 6867 "Invalid" 6866 "Invalid" 6865 "Invalid" 6864 "Invalid" 6863 "Invalid" 6862 "Invalid" 6861 "Invalid" 6860 "Invalid" 6859 "Invalid" 6858 "Invalid" 6857 "Invalid" 6856 "Invalid" 6855 "Invalid" 6854 "Invalid" 6853 "Invalid" 6852 "Invalid" 6851 "Invalid" 6850 "Invalid" 6849 "Invalid" 6848 "Invalid" 6847 "Invalid" 6846 "Invalid" 6845 "Invalid" 6844 "Invalid" 6843 "Invalid" 6842 "Invalid" 6841 "Invalid" 6840 "Invalid" 6839 "Invalid" 6838 "Invalid" 6837 "Invalid" 6836 "Invalid" 6835 "Invalid" 6834 "Invalid" 6833 "Invalid" 6832 "Invalid" 6831 "Invalid" 6830 "Invalid" 6829 "Invalid" 6828 "Invalid" 6827 "Invalid" 6826 "Invalid" 6825 "Invalid" 6824 "Invalid" 6823 "Invalid" 6822 "Invalid" 6821 "Invalid" 6820 "Invalid" 6819 "Invalid" 6818 "Invalid" 6817 "Invalid" 6816 "Invalid" 6815 "Invalid" 6814 "Invalid" 6813 "Invalid" 6812 "Invalid" 6811 "Invalid" 6810 "Invalid" 6809 "Invalid" 6808 "Invalid" 6807 "Invalid" 6806 "Invalid" 6805 "Invalid" 6804 "Invalid" 6803 "Invalid" 6802 "Invalid" 6801 "Invalid" 6800 "Invalid" 6799 "Invalid" 6798 "Invalid" 6797 "Invalid" 6796 "Invalid" 6795 "Invalid" 6794 "Invalid" 6793 "Invalid" 6792 "Invalid" 6791 "Invalid" 6790 "Invalid" 6789 "Invalid" 6788 "Invalid" 6787 "Invalid" 6786 "Invalid" 6785 "Invalid" 6784 "Invalid" 6783 "Invalid" 6782 "Invalid" 6781 "Invalid" 6780 "Invalid" 6779 "Invalid" 6778 "Invalid" 6777 "Invalid" 6776 "Invalid" 6775 "Invalid" 6774 "Invalid" 6773 "Invalid" 6772 "Invalid" 6771 "Invalid" 6770 "Invalid" 6769 "Invalid" 6768 "Invalid" 6767 "Invalid" 6766 "Invalid" 6765 "Invalid" 6764 "Invalid" 6763 "Invalid" 6762 "Invalid" 6761 "Invalid" 6760 "Invalid" 6759 "Invalid" 6758 "Invalid" 6757 "Invalid" 6756 "Invalid" 6755 "Invalid" 6754 "Invalid" 6753 "Invalid" 6752 "Invalid" 6751 "Invalid" 6750 "Invalid" 6749 "Invalid" 6748 "Invalid" 6747 "Invalid" 6746 "Invalid" 6745 "Invalid" 6744 "Invalid" 6743 "Invalid" 6742 "Invalid" 6741 "Invalid" 6740 "Invalid" 6739 "Invalid" 6738 "Invalid" 6737 "Invalid" 6736 "Invalid" 6735 "Invalid" 6734 "Invalid" 6733 "Invalid" 6732 "Invalid" 6731 "Invalid" 6730 "Invalid" 6729 "Invalid" 6728 "Invalid" 6727 "Invalid" 6726 "Invalid" 6725 "Invalid" 6724 "Invalid" 6723 "Invalid" 6722 "Invalid" 6721 "Invalid" 6720 "Invalid" 6719 "Invalid" 6718 "Invalid" 6717 "Invalid" 6716 "Invalid" 6715 "Invalid" 6714 "Invalid" 6713 "Invalid" 6712 "Invalid" 6711 "Invalid" 6710 "Invalid" 6709 "Invalid" 6708 "Invalid" 6707 "Invalid" 6706 "Invalid" 6705 "Invalid" 6704 "Invalid" 6703 "Invalid" 6702 "Invalid" 6701 "Invalid" 6700 "Invalid" 6699 "Invalid" 6698 "Invalid" 6697 "Invalid" 6696 "Invalid" 6695 "Invalid" 6694 "Invalid" 6693 "Invalid" 6692 "Invalid" 6691 "Invalid" 6690 "Invalid" 6689 "Invalid" 6688 "Invalid" 6687 "Invalid" 6686 "Invalid" 6685 "Invalid" 6684 "Invalid" 6683 "Invalid" 6682 "Invalid" 6681 "Invalid" 6680 "Invalid" 6679 "Invalid" 6678 "Invalid" 6677 "Invalid" 6676 "Invalid" 6675 "Invalid" 6674 "Invalid" 6673 "Invalid" 6672 "Invalid" 6671 "Invalid" 6670 "Invalid" 6669 "Invalid" 6668 "Invalid" 6667 "Invalid" 6666 "Invalid" 6665 "Invalid" 6664 "Invalid" 6663 "Invalid" 6662 "Invalid" 6661 "Invalid" 6660 "Invalid" 6659 "Invalid" 6658 "Invalid" 6657 "Invalid" 6656 "Invalid" 6655 "Invalid" 6654 "Invalid" 6653 "Invalid" 6652 "Invalid" 6651 "Invalid" 6650 "Invalid" 6649 "Invalid" 6648 "Invalid" 6647 "Invalid" 6646 "Invalid" 6645 "Invalid" 6644 "Invalid" 6643 "Invalid" 6642 "Invalid" 6641 "Invalid" 6640 "Invalid" 6639 "Invalid" 6638 "Invalid" 6637 "Invalid" 6636 "Invalid" 6635 "Invalid" 6634 "Invalid" 6633 "Invalid" 6632 "Invalid" 6631 "Invalid" 6630 "Invalid" 6629 "Invalid" 6628 "Invalid" 6627 "Invalid" 6626 "Invalid" 6625 "Invalid" 6624 "Invalid" 6623 "Invalid" 6622 "Invalid" 6621 "Invalid" 6620 "Invalid" 6619 "Invalid" 6618 "Invalid" 6617 "Invalid" 6616 "Invalid" 6615 "Invalid" 6614 "Invalid" 6613 "Invalid" 6612 "Invalid" 6611 "Invalid" 6610 "Invalid" 6609 "Invalid" 6608 "Invalid" 6607 "Invalid" 6606 "Invalid" 6605 "Invalid" 6604 "Invalid" 6603 "Invalid" 6602 "Invalid" 6601 "Invalid" 6600 "Invalid" 6599 "Invalid" 6598 "Invalid" 6597 "Invalid" 6596 "Invalid" 6595 "Invalid" 6594 "Invalid" 6593 "Invalid" 6592 "Invalid" 6591 "Invalid" 6590 "Invalid" 6589 "Invalid" 6588 "Invalid" 6587 "Invalid" 6586 "Invalid" 6585 "Invalid" 6584 "Invalid" 6583 "Invalid" 6582 "Invalid" 6581 "Invalid" 6580 "Invalid" 6579 "Invalid" 6578 "Invalid" 6577 "Invalid" 6576 "Invalid" 6575 "Invalid" 6574 "Invalid" 6573 "Invalid" 6572 "Invalid" 6571 "Invalid" 6570 "Invalid" 6569 "Invalid" 6568 "Invalid" 6567 "Invalid" 6566 "Invalid" 6565 "Invalid" 6564 "Invalid" 6563 "Invalid" 6562 "Invalid" 6561 "Invalid" 6560 "Invalid" 6559 "Invalid" 6558 "Invalid" 6557 "Invalid" 6556 "Invalid" 6555 "Invalid" 6554 "Invalid" 6553 "Invalid" 6552 "Invalid" 6551 "Invalid" 6550 "Invalid" 6549 "Invalid" 6548 "Invalid" 6547 "Invalid" 6546 "Invalid" 6545 "Invalid" 6544 "Invalid" 6543 "Invalid" 6542 "Invalid" 6541 "Invalid" 6540 "Invalid" 6539 "Invalid" 6538 "Invalid" 6537 "Invalid" 6536 "Invalid" 6535 "Invalid" 6534 "Invalid" 6533 "Invalid" 6532 "Invalid" 6531 "Invalid" 6530 "Invalid" 6529 "Invalid" 6528 "Invalid" 6527 "Invalid" 6526 "Invalid" 6525 "Invalid" 6524 "Invalid" 6523 "Invalid" 6522 "Invalid" 6521 "Invalid" 6520 "Invalid" 6519 "Invalid" 6518 "Invalid" 6517 "Invalid" 6516 "Invalid" 6515 "Invalid" 6514 "Invalid" 6513 "Invalid" 6512 "Invalid" 6511 "Invalid" 6510 "Invalid" 6509 "Invalid" 6508 "Invalid" 6507 "Invalid" 6506 "Invalid" 6505 "Invalid" 6504 "Invalid" 6503 "Invalid" 6502 "Invalid" 6501 "Invalid" 6500 "Invalid" 6499 "Invalid" 6498 "Invalid" 6497 "Invalid" 6496 "Invalid" 6495 "Invalid" 6494 "Invalid" 6493 "Invalid" 6492 "Invalid" 6491 "Invalid" 6490 "Invalid" 6489 "Invalid" 6488 "Invalid" 6487 "Invalid" 6486 "Invalid" 6485 "Invalid" 6484 "Invalid" 6483 "Invalid" 6482 "Invalid" 6481 "Invalid" 6480 "Invalid" 6479 "Invalid" 6478 "Invalid" 6477 "Invalid" 6476 "Invalid" 6475 "Invalid" 6474 "Invalid" 6473 "Invalid" 6472 "Invalid" 6471 "Invalid" 6470 "Invalid" 6469 "Invalid" 6468 "Invalid" 6467 "Invalid" 6466 "Invalid" 6465 "Invalid" 6464 "Invalid" 6463 "Invalid" 6462 "Invalid" 6461 "Invalid" 6460 "Invalid" 6459 "Invalid" 6458 "Invalid" 6457 "Invalid" 6456 "Invalid" 6455 "Invalid" 6454 "Invalid" 6453 "Invalid" 6452 "Invalid" 6451 "Invalid" 6450 "Invalid" 6449 "Invalid" 6448 "Invalid" 6447 "Invalid" 6446 "Invalid" 6445 "Invalid" 6444 "Invalid" 6443 "Invalid" 6442 "Invalid" 6441 "Invalid" 6440 "Invalid" 6439 "Invalid" 6438 "Invalid" 6437 "Invalid" 6436 "Invalid" 6435 "Invalid" 6434 "Invalid" 6433 "Invalid" 6432 "Invalid" 6431 "Invalid" 6430 "Invalid" 6429 "Invalid" 6428 "Invalid" 6427 "Invalid" 6426 "Invalid" 6425 "Invalid" 6424 "Invalid" 6423 "Invalid" 6422 "Invalid" 6421 "Invalid" 6420 "Invalid" 6419 "Invalid" 6418 "Invalid" 6417 "Invalid" 6416 "Invalid" 6415 "Invalid" 6414 "Invalid" 6413 "Invalid" 6412 "Invalid" 6411 "Invalid" 6410 "Invalid" 6409 "Invalid" 6408 "Invalid" 6407 "Invalid" 6406 "Invalid" 6405 "Invalid" 6404 "Invalid" 6403 "Invalid" 6402 "Invalid" 6401 "Invalid" 6400 "Invalid" 6399 "Invalid" 6398 "Invalid" 6397 "Invalid" 6396 "Invalid" 6395 "Invalid" 6394 "Invalid" 6393 "Invalid" 6392 "Invalid" 6391 "Invalid" 6390 "Invalid" 6389 "Invalid" 6388 "Invalid" 6387 "Invalid" 6386 "Invalid" 6385 "Invalid" 6384 "Invalid" 6383 "Invalid" 6382 "Invalid" 6381 "Invalid" 6380 "Invalid" 6379 "Invalid" 6378 "Invalid" 6377 "Invalid" 6376 "Invalid" 6375 "Invalid" 6374 "Invalid" 6373 "Invalid" 6372 "Invalid" 6371 "Invalid" 6370 "Invalid" 6369 "Invalid" 6368 "Invalid" 6367 "Invalid" 6366 "Invalid" 6365 "Invalid" 6364 "Invalid" 6363 "Invalid" 6362 "Invalid" 6361 "Invalid" 6360 "Invalid" 6359 "Invalid" 6358 "Invalid" 6357 "Invalid" 6356 "Invalid" 6355 "Invalid" 6354 "Invalid" 6353 "Invalid" 6352 "Invalid" 6351 "Invalid" 6350 "Invalid" 6349 "Invalid" 6348 "Invalid" 6347 "Invalid" 6346 "Invalid" 6345 "Invalid" 6344 "Invalid" 6343 "Invalid" 6342 "Invalid" 6341 "Invalid" 6340 "Invalid" 6339 "Invalid" 6338 "Invalid" 6337 "Invalid" 6336 "Invalid" 6335 "Invalid" 6334 "Invalid" 6333 "Invalid" 6332 "Invalid" 6331 "Invalid" 6330 "Invalid" 6329 "Invalid" 6328 "Invalid" 6327 "Invalid" 6326 "Invalid" 6325 "Invalid" 6324 "Invalid" 6323 "Invalid" 6322 "Invalid" 6321 "Invalid" 6320 "Invalid" 6319 "Invalid" 6318 "Invalid" 6317 "Invalid" 6316 "Invalid" 6315 "Invalid" 6314 "Invalid" 6313 "Invalid" 6312 "Invalid" 6311 "Invalid" 6310 "Invalid" 6309 "Invalid" 6308 "Invalid" 6307 "Invalid" 6306 "Invalid" 6305 "Invalid" 6304 "Invalid" 6303 "Invalid" 6302 "Invalid" 6301 "Invalid" 6300 "Invalid" 6299 "Invalid" 6298 "Invalid" 6297 "Invalid" 6296 "Invalid" 6295 "Invalid" 6294 "Invalid" 6293 "Invalid" 6292 "Invalid" 6291 "Invalid" 6290 "Invalid" 6289 "Invalid" 6288 "Invalid" 6287 "Invalid" 6286 "Invalid" 6285 "Invalid" 6284 "Invalid" 6283 "Invalid" 6282 "Invalid" 6281 "Invalid" 6280 "Invalid" 6279 "Invalid" 6278 "Invalid" 6277 "Invalid" 6276 "Invalid" 6275 "Invalid" 6274 "Invalid" 6273 "Invalid" 6272 "Invalid" 6271 "Invalid" 6270 "Invalid" 6269 "Invalid" 6268 "Invalid" 6267 "Invalid" 6266 "Invalid" 6265 "Invalid" 6264 "Invalid" 6263 "Invalid" 6262 "Invalid" 6261 "Invalid" 6260 "Invalid" 6259 "Invalid" 6258 "Invalid" 6257 "Invalid" 6256 "Invalid" 6255 "Invalid" 6254 "Invalid" 6253 "Invalid" 6252 "Invalid" 6251 "Invalid" 6250 "Invalid" 6249 "Invalid" 6248 "Invalid" 6247 "Invalid" 6246 "Invalid" 6245 "Invalid" 6244 "Invalid" 6243 "Invalid" 6242 "Invalid" 6241 "Invalid" 6240 "Invalid" 6239 "Invalid" 6238 "Invalid" 6237 "Invalid" 6236 "Invalid" 6235 "Invalid" 6234 "Invalid" 6233 "Invalid" 6232 "Invalid" 6231 "Invalid" 6230 "Invalid" 6229 "Invalid" 6228 "Invalid" 6227 "Invalid" 6226 "Invalid" 6225 "Invalid" 6224 "Invalid" 6223 "Invalid" 6222 "Invalid" 6221 "Invalid" 6220 "Invalid" 6219 "Invalid" 6218 "Invalid" 6217 "Invalid" 6216 "Invalid" 6215 "Invalid" 6214 "Invalid" 6213 "Invalid" 6212 "Invalid" 6211 "Invalid" 6210 "Invalid" 6209 "Invalid" 6208 "Invalid" 6207 "Invalid" 6206 "Invalid" 6205 "Invalid" 6204 "Invalid" 6203 "Invalid" 6202 "Invalid" 6201 "Invalid" 6200 "Invalid" 6199 "Invalid" 6198 "Invalid" 6197 "Invalid" 6196 "Invalid" 6195 "Invalid" 6194 "Invalid" 6193 "Invalid" 6192 "Invalid" 6191 "Invalid" 6190 "Invalid" 6189 "Invalid" 6188 "Invalid" 6187 "Invalid" 6186 "Invalid" 6185 "Invalid" 6184 "Invalid" 6183 "Invalid" 6182 "Invalid" 6181 "Invalid" 6180 "Invalid" 6179 "Invalid" 6178 "Invalid" 6177 "Invalid" 6176 "Invalid" 6175 "Invalid" 6174 "Invalid" 6173 "Invalid" 6172 "Invalid" 6171 "Invalid" 6170 "Invalid" 6169 "Invalid" 6168 "Invalid" 6167 "Invalid" 6166 "Invalid" 6165 "Invalid" 6164 "Invalid" 6163 "Invalid" 6162 "Invalid" 6161 "Invalid" 6160 "Invalid" 6159 "Invalid" 6158 "Invalid" 6157 "Invalid" 6156 "Invalid" 6155 "Invalid" 6154 "Invalid" 6153 "Invalid" 6152 "Invalid" 6151 "Invalid" 6150 "Invalid" 6149 "Invalid" 6148 "Invalid" 6147 "Invalid" 6146 "Invalid" 6145 "Invalid" 6144 "Invalid" 6143 "Invalid" 6142 "Invalid" 6141 "Invalid" 6140 "Invalid" 6139 "Invalid" 6138 "Invalid" 6137 "Invalid" 6136 "Invalid" 6135 "Invalid" 6134 "Invalid" 6133 "Invalid" 6132 "Invalid" 6131 "Invalid" 6130 "Invalid" 6129 "Invalid" 6128 "Invalid" 6127 "Invalid" 6126 "Invalid" 6125 "Invalid" 6124 "Invalid" 6123 "Invalid" 6122 "Invalid" 6121 "Invalid" 6120 "Invalid" 6119 "Invalid" 6118 "Invalid" 6117 "Invalid" 6116 "Invalid" 6115 "Invalid" 6114 "Invalid" 6113 "Invalid" 6112 "Invalid" 6111 "Invalid" 6110 "Invalid" 6109 "Invalid" 6108 "Invalid" 6107 "Invalid" 6106 "Invalid" 6105 "Invalid" 6104 "Invalid" 6103 "Invalid" 6102 "Invalid" 6101 "Invalid" 6100 "Invalid" 6099 "Invalid" 6098 "Invalid" 6097 "Invalid" 6096 "Invalid" 6095 "Invalid" 6094 "Invalid" 6093 "Invalid" 6092 "Invalid" 6091 "Invalid" 6090 "Invalid" 6089 "Invalid" 6088 "Invalid" 6087 "Invalid" 6086 "Invalid" 6085 "Invalid" 6084 "Invalid" 6083 "Invalid" 6082 "Invalid" 6081 "Invalid" 6080 "Invalid" 6079 "Invalid" 6078 "Invalid" 6077 "Invalid" 6076 "Invalid" 6075 "Invalid" 6074 "Invalid" 6073 "Invalid" 6072 "Invalid" 6071 "Invalid" 6070 "Invalid" 6069 "Invalid" 6068 "Invalid" 6067 "Invalid" 6066 "Invalid" 6065 "Invalid" 6064 "Invalid" 6063 "Invalid" 6062 "Invalid" 6061 "Invalid" 6060 "Invalid" 6059 "Invalid" 6058 "Invalid" 6057 "Invalid" 6056 "Invalid" 6055 "Invalid" 6054 "Invalid" 6053 "Invalid" 6052 "Invalid" 6051 "Invalid" 6050 "Invalid" 6049 "Invalid" 6048 "Invalid" 6047 "Invalid" 6046 "Invalid" 6045 "Invalid" 6044 "Invalid" 6043 "Invalid" 6042 "Invalid" 6041 "Invalid" 6040 "Invalid" 6039 "Invalid" 6038 "Invalid" 6037 "Invalid" 6036 "Invalid" 6035 "Invalid" 6034 "Invalid" 6033 "Invalid" 6032 "Invalid" 6031 "Invalid" 6030 "Invalid" 6029 "Invalid" 6028 "Invalid" 6027 "Invalid" 6026 "Invalid" 6025 "Invalid" 6024 "Invalid" 6023 "Invalid" 6022 "Invalid" 6021 "Invalid" 6020 "Invalid" 6019 "Invalid" 6018 "Invalid" 6017 "Invalid" 6016 "Invalid" 6015 "Invalid" 6014 "Invalid" 6013 "Invalid" 6012 "Invalid" 6011 "Invalid" 6010 "Invalid" 6009 "Invalid" 6008 "Invalid" 6007 "Invalid" 6006 "Invalid" 6005 "Invalid" 6004 "Invalid" 6003 "Invalid" 6002 "Invalid" 6001 "Invalid" 6000 "Invalid" 5999 "Invalid" 5998 "Invalid" 5997 "Invalid" 5996 "Invalid" 5995 "Invalid" 5994 "Invalid" 5993 "Invalid" 5992 "Invalid" 5991 "Invalid" 5990 "Invalid" 5989 "Invalid" 5988 "Invalid" 5987 "Invalid" 5986 "Invalid" 5985 "Invalid" 5984 "Invalid" 5983 "Invalid" 5982 "Invalid" 5981 "Invalid" 5980 "Invalid" 5979 "Invalid" 5978 "Invalid" 5977 "Invalid" 5976 "Invalid" 5975 "Invalid" 5974 "Invalid" 5973 "Invalid" 5972 "Invalid" 5971 "Invalid" 5970 "Invalid" 5969 "Invalid" 5968 "Invalid" 5967 "Invalid" 5966 "Invalid" 5965 "Invalid" 5964 "Invalid" 5963 "Invalid" 5962 "Invalid" 5961 "Invalid" 5960 "Invalid" 5959 "Invalid" 5958 "Invalid" 5957 "Invalid" 5956 "Invalid" 5955 "Invalid" 5954 "Invalid" 5953 "Invalid" 5952 "Invalid" 5951 "Invalid" 5950 "Invalid" 5949 "Invalid" 5948 "Invalid" 5947 "Invalid" 5946 "Invalid" 5945 "Invalid" 5944 "Invalid" 5943 "Invalid" 5942 "Invalid" 5941 "Invalid" 5940 "Invalid" 5939 "Invalid" 5938 "Invalid" 5937 "Invalid" 5936 "Invalid" 5935 "Invalid" 5934 "Invalid" 5933 "Invalid" 5932 "Invalid" 5931 "Invalid" 5930 "Invalid" 5929 "Invalid" 5928 "Invalid" 5927 "Invalid" 5926 "Invalid" 5925 "Invalid" 5924 "Invalid" 5923 "Invalid" 5922 "Invalid" 5921 "Invalid" 5920 "Invalid" 5919 "Invalid" 5918 "Invalid" 5917 "Invalid" 5916 "Invalid" 5915 "Invalid" 5914 "Invalid" 5913 "Invalid" 5912 "Invalid" 5911 "Invalid" 5910 "Invalid" 5909 "Invalid" 5908 "Invalid" 5907 "Invalid" 5906 "Invalid" 5905 "Invalid" 5904 "Invalid" 5903 "Invalid" 5902 "Invalid" 5901 "Invalid" 5900 "Invalid" 5899 "Invalid" 5898 "Invalid" 5897 "Invalid" 5896 "Invalid" 5895 "Invalid" 5894 "Invalid" 5893 "Invalid" 5892 "Invalid" 5891 "Invalid" 5890 "Invalid" 5889 "Invalid" 5888 "Invalid" 5887 "Invalid" 5886 "Invalid" 5885 "Invalid" 5884 "Invalid" 5883 "Invalid" 5882 "Invalid" 5881 "Invalid" 5880 "Invalid" 5879 "Invalid" 5878 "Invalid" 5877 "Invalid" 5876 "Invalid" 5875 "Invalid" 5874 "Invalid" 5873 "Invalid" 5872 "Invalid" 5871 "Invalid" 5870 "Invalid" 5869 "Invalid" 5868 "Invalid" 5867 "Invalid" 5866 "Invalid" 5865 "Invalid" 5864 "Invalid" 5863 "Invalid" 5862 "Invalid" 5861 "Invalid" 5860 "Invalid" 5859 "Invalid" 5858 "Invalid" 5857 "Invalid" 5856 "Invalid" 5855 "Invalid" 5854 "Invalid" 5853 "Invalid" 5852 "Invalid" 5851 "Invalid" 5850 "Invalid" 5849 "Invalid" 5848 "Invalid" 5847 "Invalid" 5846 "Invalid" 5845 "Invalid" 5844 "Invalid" 5843 "Invalid" 5842 "Invalid" 5841 "Invalid" 5840 "Invalid" 5839 "Invalid" 5838 "Invalid" 5837 "Invalid" 5836 "Invalid" 5835 "Invalid" 5834 "Invalid" 5833 "Invalid" 5832 "Invalid" 5831 "Invalid" 5830 "Invalid" 5829 "Invalid" 5828 "Invalid" 5827 "Invalid" 5826 "Invalid" 5825 "Invalid" 5824 "Invalid" 5823 "Invalid" 5822 "Invalid" 5821 "Invalid" 5820 "Invalid" 5819 "Invalid" 5818 "Invalid" 5817 "Invalid" 5816 "Invalid" 5815 "Invalid" 5814 "Invalid" 5813 "Invalid" 5812 "Invalid" 5811 "Invalid" 5810 "Invalid" 5809 "Invalid" 5808 "Invalid" 5807 "Invalid" 5806 "Invalid" 5805 "Invalid" 5804 "Invalid" 5803 "Invalid" 5802 "Invalid" 5801 "Invalid" 5800 "Invalid" 5799 "Invalid" 5798 "Invalid" 5797 "Invalid" 5796 "Invalid" 5795 "Invalid" 5794 "Invalid" 5793 "Invalid" 5792 "Invalid" 5791 "Invalid" 5790 "Invalid" 5789 "Invalid" 5788 "Invalid" 5787 "Invalid" 5786 "Invalid" 5785 "Invalid" 5784 "Invalid" 5783 "Invalid" 5782 "Invalid" 5781 "Invalid" 5780 "Invalid" 5779 "Invalid" 5778 "Invalid" 5777 "Invalid" 5776 "Invalid" 5775 "Invalid" 5774 "Invalid" 5773 "Invalid" 5772 "Invalid" 5771 "Invalid" 5770 "Invalid" 5769 "Invalid" 5768 "Invalid" 5767 "Invalid" 5766 "Invalid" 5765 "Invalid" 5764 "Invalid" 5763 "Invalid" 5762 "Invalid" 5761 "Invalid" 5760 "Invalid" 5759 "Invalid" 5758 "Invalid" 5757 "Invalid" 5756 "Invalid" 5755 "Invalid" 5754 "Invalid" 5753 "Invalid" 5752 "Invalid" 5751 "Invalid" 5750 "Invalid" 5749 "Invalid" 5748 "Invalid" 5747 "Invalid" 5746 "Invalid" 5745 "Invalid" 5744 "Invalid" 5743 "Invalid" 5742 "Invalid" 5741 "Invalid" 5740 "Invalid" 5739 "Invalid" 5738 "Invalid" 5737 "Invalid" 5736 "Invalid" 5735 "Invalid" 5734 "Invalid" 5733 "Invalid" 5732 "Invalid" 5731 "Invalid" 5730 "Invalid" 5729 "Invalid" 5728 "Invalid" 5727 "Invalid" 5726 "Invalid" 5725 "Invalid" 5724 "Invalid" 5723 "Invalid" 5722 "Invalid" 5721 "Invalid" 5720 "Invalid" 5719 "Invalid" 5718 "Invalid" 5717 "Invalid" 5716 "Invalid" 5715 "Invalid" 5714 "Invalid" 5713 "Invalid" 5712 "Invalid" 5711 "Invalid" 5710 "Invalid" 5709 "Invalid" 5708 "Invalid" 5707 "Invalid" 5706 "Invalid" 5705 "Invalid" 5704 "Invalid" 5703 "Invalid" 5702 "Invalid" 5701 "Invalid" 5700 "Invalid" 5699 "Invalid" 5698 "Invalid" 5697 "Invalid" 5696 "Invalid" 5695 "Invalid" 5694 "Invalid" 5693 "Invalid" 5692 "Invalid" 5691 "Invalid" 5690 "Invalid" 5689 "Invalid" 5688 "Invalid" 5687 "Invalid" 5686 "Invalid" 5685 "Invalid" 5684 "Invalid" 5683 "Invalid" 5682 "Invalid" 5681 "Invalid" 5680 "Invalid" 5679 "Invalid" 5678 "Invalid" 5677 "Invalid" 5676 "Invalid" 5675 "Invalid" 5674 "Invalid" 5673 "Invalid" 5672 "Invalid" 5671 "Invalid" 5670 "Invalid" 5669 "Invalid" 5668 "Invalid" 5667 "Invalid" 5666 "Invalid" 5665 "Invalid" 5664 "Invalid" 5663 "Invalid" 5662 "Invalid" 5661 "Invalid" 5660 "Invalid" 5659 "Invalid" 5658 "Invalid" 5657 "Invalid" 5656 "Invalid" 5655 "Invalid" 5654 "Invalid" 5653 "Invalid" 5652 "Invalid" 5651 "Invalid" 5650 "Invalid" 5649 "Invalid" 5648 "Invalid" 5647 "Invalid" 5646 "Invalid" 5645 "Invalid" 5644 "Invalid" 5643 "Invalid" 5642 "Invalid" 5641 "Invalid" 5640 "Invalid" 5639 "Invalid" 5638 "Invalid" 5637 "Invalid" 5636 "Invalid" 5635 "Invalid" 5634 "Invalid" 5633 "Invalid" 5632 "Invalid" 5631 "Invalid" 5630 "Invalid" 5629 "Invalid" 5628 "Invalid" 5627 "Invalid" 5626 "Invalid" 5625 "Invalid" 5624 "Invalid" 5623 "Invalid" 5622 "Invalid" 5621 "Invalid" 5620 "Invalid" 5619 "Invalid" 5618 "Invalid" 5617 "Invalid" 5616 "Invalid" 5615 "Invalid" 5614 "Invalid" 5613 "Invalid" 5612 "Invalid" 5611 "Invalid" 5610 "Invalid" 5609 "Invalid" 5608 "Invalid" 5607 "Invalid" 5606 "Invalid" 5605 "Invalid" 5604 "Invalid" 5603 "Invalid" 5602 "Invalid" 5601 "Invalid" 5600 "Invalid" 5599 "Invalid" 5598 "Invalid" 5597 "Invalid" 5596 "Invalid" 5595 "Invalid" 5594 "Invalid" 5593 "Invalid" 5592 "Invalid" 5591 "Invalid" 5590 "Invalid" 5589 "Invalid" 5588 "Invalid" 5587 "Invalid" 5586 "Invalid" 5585 "Invalid" 5584 "Invalid" 5583 "Invalid" 5582 "Invalid" 5581 "Invalid" 5580 "Invalid" 5579 "Invalid" 5578 "Invalid" 5577 "Invalid" 5576 "Invalid" 5575 "Invalid" 5574 "Invalid" 5573 "Invalid" 5572 "Invalid" 5571 "Invalid" 5570 "Invalid" 5569 "Invalid" 5568 "Invalid" 5567 "Invalid" 5566 "Invalid" 5565 "Invalid" 5564 "Invalid" 5563 "Invalid" 5562 "Invalid" 5561 "Invalid" 5560 "Invalid" 5559 "Invalid" 5558 "Invalid" 5557 "Invalid" 5556 "Invalid" 5555 "Invalid" 5554 "Invalid" 5553 "Invalid" 5552 "Invalid" 5551 "Invalid" 5550 "Invalid" 5549 "Invalid" 5548 "Invalid" 5547 "Invalid" 5546 "Invalid" 5545 "Invalid" 5544 "Invalid" 5543 "Invalid" 5542 "Invalid" 5541 "Invalid" 5540 "Invalid" 5539 "Invalid" 5538 "Invalid" 5537 "Invalid" 5536 "Invalid" 5535 "Invalid" 5534 "Invalid" 5533 "Invalid" 5532 "Invalid" 5531 "Invalid" 5530 "Invalid" 5529 "Invalid" 5528 "Invalid" 5527 "Invalid" 5526 "Invalid" 5525 "Invalid" 5524 "Invalid" 5523 "Invalid" 5522 "Invalid" 5521 "Invalid" 5520 "Invalid" 5519 "Invalid" 5518 "Invalid" 5517 "Invalid" 5516 "Invalid" 5515 "Invalid" 5514 "Invalid" 5513 "Invalid" 5512 "Invalid" 5511 "Invalid" 5510 "Invalid" 5509 "Invalid" 5508 "Invalid" 5507 "Invalid" 5506 "Invalid" 5505 "Invalid" 5504 "Invalid" 5503 "Invalid" 5502 "Invalid" 5501 "Invalid" 5500 "Invalid" 5499 "Invalid" 5498 "Invalid" 5497 "Invalid" 5496 "Invalid" 5495 "Invalid" 5494 "Invalid" 5493 "Invalid" 5492 "Invalid" 5491 "Invalid" 5490 "Invalid" 5489 "Invalid" 5488 "Invalid" 5487 "Invalid" 5486 "Invalid" 5485 "Invalid" 5484 "Invalid" 5483 "Invalid" 5482 "Invalid" 5481 "Invalid" 5480 "Invalid" 5479 "Invalid" 5478 "Invalid" 5477 "Invalid" 5476 "Invalid" 5475 "Invalid" 5474 "Invalid" 5473 "Invalid" 5472 "Invalid" 5471 "Invalid" 5470 "Invalid" 5469 "Invalid" 5468 "Invalid" 5467 "Invalid" 5466 "Invalid" 5465 "Invalid" 5464 "Invalid" 5463 "Invalid" 5462 "Invalid" 5461 "Invalid" 5460 "Invalid" 5459 "Invalid" 5458 "Invalid" 5457 "Invalid" 5456 "Invalid" 5455 "Invalid" 5454 "Invalid" 5453 "Invalid" 5452 "Invalid" 5451 "Invalid" 5450 "Invalid" 5449 "Invalid" 5448 "Invalid" 5447 "Invalid" 5446 "Invalid" 5445 "Invalid" 5444 "Invalid" 5443 "Invalid" 5442 "Invalid" 5441 "Invalid" 5440 "Invalid" 5439 "Invalid" 5438 "Invalid" 5437 "Invalid" 5436 "Invalid" 5435 "Invalid" 5434 "Invalid" 5433 "Invalid" 5432 "Invalid" 5431 "Invalid" 5430 "Invalid" 5429 "Invalid" 5428 "Invalid" 5427 "Invalid" 5426 "Invalid" 5425 "Invalid" 5424 "Invalid" 5423 "Invalid" 5422 "Invalid" 5421 "Invalid" 5420 "Invalid" 5419 "Invalid" 5418 "Invalid" 5417 "Invalid" 5416 "Invalid" 5415 "Invalid" 5414 "Invalid" 5413 "Invalid" 5412 "Invalid" 5411 "Invalid" 5410 "Invalid" 5409 "Invalid" 5408 "Invalid" 5407 "Invalid" 5406 "Invalid" 5405 "Invalid" 5404 "Invalid" 5403 "Invalid" 5402 "Invalid" 5401 "Invalid" 5400 "Invalid" 5399 "Invalid" 5398 "Invalid" 5397 "Invalid" 5396 "Invalid" 5395 "Invalid" 5394 "Invalid" 5393 "Invalid" 5392 "Invalid" 5391 "Invalid" 5390 "Invalid" 5389 "Invalid" 5388 "Invalid" 5387 "Invalid" 5386 "Invalid" 5385 "Invalid" 5384 "Invalid" 5383 "Invalid" 5382 "Invalid" 5381 "Invalid" 5380 "Invalid" 5379 "Invalid" 5378 "Invalid" 5377 "Invalid" 5376 "Invalid" 5375 "Invalid" 5374 "Invalid" 5373 "Invalid" 5372 "Invalid" 5371 "Invalid" 5370 "Invalid" 5369 "Invalid" 5368 "Invalid" 5367 "Invalid" 5366 "Invalid" 5365 "Invalid" 5364 "Invalid" 5363 "Invalid" 5362 "Invalid" 5361 "Invalid" 5360 "Invalid" 5359 "Invalid" 5358 "Invalid" 5357 "Invalid" 5356 "Invalid" 5355 "Invalid" 5354 "Invalid" 5353 "Invalid" 5352 "Invalid" 5351 "Invalid" 5350 "Invalid" 5349 "Invalid" 5348 "Invalid" 5347 "Invalid" 5346 "Invalid" 5345 "Invalid" 5344 "Invalid" 5343 "Invalid" 5342 "Invalid" 5341 "Invalid" 5340 "Invalid" 5339 "Invalid" 5338 "Invalid" 5337 "Invalid" 5336 "Invalid" 5335 "Invalid" 5334 "Invalid" 5333 "Invalid" 5332 "Invalid" 5331 "Invalid" 5330 "Invalid" 5329 "Invalid" 5328 "Invalid" 5327 "Invalid" 5326 "Invalid" 5325 "Invalid" 5324 "Invalid" 5323 "Invalid" 5322 "Invalid" 5321 "Invalid" 5320 "Invalid" 5319 "Invalid" 5318 "Invalid" 5317 "Invalid" 5316 "Invalid" 5315 "Invalid" 5314 "Invalid" 5313 "Invalid" 5312 "Invalid" 5311 "Invalid" 5310 "Invalid" 5309 "Invalid" 5308 "Invalid" 5307 "Invalid" 5306 "Invalid" 5305 "Invalid" 5304 "Invalid" 5303 "Invalid" 5302 "Invalid" 5301 "Invalid" 5300 "Invalid" 5299 "Invalid" 5298 "Invalid" 5297 "Invalid" 5296 "Invalid" 5295 "Invalid" 5294 "Invalid" 5293 "Invalid" 5292 "Invalid" 5291 "Invalid" 5290 "Invalid" 5289 "Invalid" 5288 "Invalid" 5287 "Invalid" 5286 "Invalid" 5285 "Invalid" 5284 "Invalid" 5283 "Invalid" 5282 "Invalid" 5281 "Invalid" 5280 "Invalid" 5279 "Invalid" 5278 "Invalid" 5277 "Invalid" 5276 "Invalid" 5275 "Invalid" 5274 "Invalid" 5273 "Invalid" 5272 "Invalid" 5271 "Invalid" 5270 "Invalid" 5269 "Invalid" 5268 "Invalid" 5267 "Invalid" 5266 "Invalid" 5265 "Invalid" 5264 "Invalid" 5263 "Invalid" 5262 "Invalid" 5261 "Invalid" 5260 "Invalid" 5259 "Invalid" 5258 "Invalid" 5257 "Invalid" 5256 "Invalid" 5255 "Invalid" 5254 "Invalid" 5253 "Invalid" 5252 "Invalid" 5251 "Invalid" 5250 "Invalid" 5249 "Invalid" 5248 "Invalid" 5247 "Invalid" 5246 "Invalid" 5245 "Invalid" 5244 "Invalid" 5243 "Invalid" 5242 "Invalid" 5241 "Invalid" 5240 "Invalid" 5239 "Invalid" 5238 "Invalid" 5237 "Invalid" 5236 "Invalid" 5235 "Invalid" 5234 "Invalid" 5233 "Invalid" 5232 "Invalid" 5231 "Invalid" 5230 "Invalid" 5229 "Invalid" 5228 "Invalid" 5227 "Invalid" 5226 "Invalid" 5225 "Invalid" 5224 "Invalid" 5223 "Invalid" 5222 "Invalid" 5221 "Invalid" 5220 "Invalid" 5219 "Invalid" 5218 "Invalid" 5217 "Invalid" 5216 "Invalid" 5215 "Invalid" 5214 "Invalid" 5213 "Invalid" 5212 "Invalid" 5211 "Invalid" 5210 "Invalid" 5209 "Invalid" 5208 "Invalid" 5207 "Invalid" 5206 "Invalid" 5205 "Invalid" 5204 "Invalid" 5203 "Invalid" 5202 "Invalid" 5201 "Invalid" 5200 "Invalid" 5199 "Invalid" 5198 "Invalid" 5197 "Invalid" 5196 "Invalid" 5195 "Invalid" 5194 "Invalid" 5193 "Invalid" 5192 "Invalid" 5191 "Invalid" 5190 "Invalid" 5189 "Invalid" 5188 "Invalid" 5187 "Invalid" 5186 "Invalid" 5185 "Invalid" 5184 "Invalid" 5183 "Invalid" 5182 "Invalid" 5181 "Invalid" 5180 "Invalid" 5179 "Invalid" 5178 "Invalid" 5177 "Invalid" 5176 "Invalid" 5175 "Invalid" 5174 "Invalid" 5173 "Invalid" 5172 "Invalid" 5171 "Invalid" 5170 "Invalid" 5169 "Invalid" 5168 "Invalid" 5167 "Invalid" 5166 "Invalid" 5165 "Invalid" 5164 "Invalid" 5163 "Invalid" 5162 "Invalid" 5161 "Invalid" 5160 "Invalid" 5159 "Invalid" 5158 "Invalid" 5157 "Invalid" 5156 "Invalid" 5155 "Invalid" 5154 "Invalid" 5153 "Invalid" 5152 "Invalid" 5151 "Invalid" 5150 "Invalid" 5149 "Invalid" 5148 "Invalid" 5147 "Invalid" 5146 "Invalid" 5145 "Invalid" 5144 "Invalid" 5143 "Invalid" 5142 "Invalid" 5141 "Invalid" 5140 "Invalid" 5139 "Invalid" 5138 "Invalid" 5137 "Invalid" 5136 "Invalid" 5135 "Invalid" 5134 "Invalid" 5133 "Invalid" 5132 "Invalid" 5131 "Invalid" 5130 "Invalid" 5129 "Invalid" 5128 "Invalid" 5127 "Invalid" 5126 "Invalid" 5125 "Invalid" 5124 "Invalid" 5123 "Invalid" 5122 "Invalid" 5121 "Invalid" 5120 "Invalid" 5119 "Invalid" 5118 "Invalid" 5117 "Invalid" 5116 "Invalid" 5115 "Invalid" 5114 "Invalid" 5113 "Invalid" 5112 "Invalid" 5111 "Invalid" 5110 "Invalid" 5109 "Invalid" 5108 "Invalid" 5107 "Invalid" 5106 "Invalid" 5105 "Invalid" 5104 "Invalid" 5103 "Invalid" 5102 "Invalid" 5101 "Invalid" 5100 "Invalid" 5099 "Invalid" 5098 "Invalid" 5097 "Invalid" 5096 "Invalid" 5095 "Invalid" 5094 "Invalid" 5093 "Invalid" 5092 "Invalid" 5091 "Invalid" 5090 "Invalid" 5089 "Invalid" 5088 "Invalid" 5087 "Invalid" 5086 "Invalid" 5085 "Invalid" 5084 "Invalid" 5083 "Invalid" 5082 "Invalid" 5081 "Invalid" 5080 "Invalid" 5079 "Invalid" 5078 "Invalid" 5077 "Invalid" 5076 "Invalid" 5075 "Invalid" 5074 "Invalid" 5073 "Invalid" 5072 "Invalid" 5071 "Invalid" 5070 "Invalid" 5069 "Invalid" 5068 "Invalid" 5067 "Invalid" 5066 "Invalid" 5065 "Invalid" 5064 "Invalid" 5063 "Invalid" 5062 "Invalid" 5061 "Invalid" 5060 "Invalid" 5059 "Invalid" 5058 "Invalid" 5057 "Invalid" 5056 "Invalid" 5055 "Invalid" 5054 "Invalid" 5053 "Invalid" 5052 "Invalid" 5051 "Invalid" 5050 "Invalid" 5049 "Invalid" 5048 "Invalid" 5047 "Invalid" 5046 "Invalid" 5045 "Invalid" 5044 "Invalid" 5043 "Invalid" 5042 "Invalid" 5041 "Invalid" 5040 "Invalid" 5039 "Invalid" 5038 "Invalid" 5037 "Invalid" 5036 "Invalid" 5035 "Invalid" 5034 "Invalid" 5033 "Invalid" 5032 "Invalid" 5031 "Invalid" 5030 "Invalid" 5029 "Invalid" 5028 "Invalid" 5027 "Invalid" 5026 "Invalid" 5025 "Invalid" 5024 "Invalid" 5023 "Invalid" 5022 "Invalid" 5021 "Invalid" 5020 "Invalid" 5019 "Invalid" 5018 "Invalid" 5017 "Invalid" 5016 "Invalid" 5015 "Invalid" 5014 "Invalid" 5013 "Invalid" 5012 "Invalid" 5011 "Invalid" 5010 "Invalid" 5009 "Invalid" 5008 "Invalid" 5007 "Invalid" 5006 "Invalid" 5005 "Invalid" 5004 "Invalid" 5003 "Invalid" 5002 "Invalid" 5001 "Invalid" ;
VAL_ 529 BCU_BattLoTmpHeatAccsOnAllwd 3 "Reserved" 2 "Request off" 1 "Request on" 0 "Default" ;
VAL_ 529 BCU_SOE 1023 "Invalid" 1022 "Invalid" 1021 "Invalid" 1020 "Invalid" 1019 "Invalid" 1018 "Invalid" 1017 "Invalid" 1016 "Invalid" 1015 "Invalid" 1014 "Invalid" 1013 "Invalid" 1012 "Invalid" 1011 "Invalid" 1010 "Invalid" 1009 "Invalid" 1008 "Invalid" 1007 "Invalid" 1006 "Invalid" 1005 "Invalid" 1004 "Invalid" 1003 "Invalid" 1002 "Invalid" 1001 "Invalid" ;
VAL_ 529 BCU_BattSysFltInd 3 "Reserved" 2 "Error" 1 "Fault" 0 "No fault" ;
VAL_ 529 BCU_BattThrmMngReq 7 "Reserved" 6 "Reserved" 5 "Battery Thermo balance" 4 "self-adaption heat" 3 "Max power heat" 2 "self-adaption coolent" 1 "Max power coolent" 0 "No need" ;
VAL_ 529 BCU_BattThrmTrgetTemp 255 "Invalid" 254 "Invalid" 253 "Invalid" 252 "Invalid" 251 "Invalid" 250 "Invalid" 249 "Invalid" 248 "Invalid" 247 "Invalid" 246 "Invalid" 245 "Invalid" 244 "Invalid" 243 "Invalid" 242 "Invalid" 241 "Invalid" 240 "Invalid" 239 "Invalid" 238 "Invalid" 237 "Invalid" 236 "Invalid" 235 "Invalid" 234 "Invalid" 233 "Invalid" 232 "Invalid" 231 "Invalid" 230 "Invalid" 229 "Invalid" 228 "Invalid" 227 "Invalid" 226 "Invalid" 225 "Invalid" 224 "Invalid" 223 "Invalid" 222 "Invalid" 221 "Invalid" 220 "Invalid" 219 "Invalid" 218 "Invalid" 217 "Invalid" 216 "Invalid" 215 "Invalid" 214 "Invalid" 213 "Invalid" 212 "Invalid" 211 "Invalid" 210 "Invalid" 209 "Invalid" 208 "Invalid" 207 "Invalid" 206 "Invalid" 205 "Invalid" 204 "Invalid" 203 "Invalid" 202 "Invalid" 201 "Invalid" 200 "Invalid" 199 "Invalid" 198 "Invalid" 197 "Invalid" 196 "Invalid" 195 "Invalid" 194 "Invalid" 193 "Invalid" 192 "Invalid" 191 "Invalid" 190 "Invalid" 189 "Invalid" 188 "Invalid" 187 "Invalid" 186 "Invalid" 185 "Invalid" 184 "Invalid" 183 "Invalid" 182 "Invalid" 181 "Invalid" 180 "Invalid" 179 "Invalid" 178 "Invalid" 177 "Invalid" 176 "Invalid" 175 "Invalid" 174 "Invalid" 173 "Invalid" 172 "Invalid" 171 "Invalid" 170 "Invalid" 169 "Invalid" 168 "Invalid" 167 "Invalid" 166 "Invalid" 165 "Invalid" 164 "Invalid" 163 "Invalid" 162 "Invalid" 161 "Invalid" ;
VAL_ 535 BCU_MaxModlTmp 255 "Invalid" 254 "Invalid" 253 "Invalid" 252 "Invalid" 251 "Invalid" 250 "Invalid" 249 "Invalid" 248 "Invalid" 247 "Invalid" 246 "Invalid" 245 "Invalid" 244 "Invalid" 243 "Invalid" 242 "Invalid" 241 "Invalid" 240 "Invalid" 239 "Invalid" 238 "Invalid" 237 "Invalid" 236 "Invalid" 235 "Invalid" 234 "Invalid" 233 "Invalid" 232 "Invalid" 231 "Invalid" 230 "Invalid" 229 "Invalid" 228 "Invalid" 227 "Invalid" 226 "Invalid" 225 "Invalid" 224 "Invalid" 223 "Invalid" 222 "Invalid" 221 "Invalid" 220 "Invalid" 219 "Invalid" 218 "Invalid" 217 "Invalid" 216 "Invalid" 215 "Invalid" 214 "Invalid" 213 "Invalid" 212 "Invalid" 211 "Invalid" 210 "Invalid" 209 "Invalid" 208 "Invalid" 207 "Invalid" 206 "Invalid" 205 "Invalid" 204 "Invalid" 203 "Invalid" 202 "Invalid" 201 "Invalid" 200 "Invalid" 199 "Invalid" 198 "Invalid" 197 "Invalid" 196 "Invalid" 195 "Invalid" 194 "Invalid" 193 "Invalid" 192 "Invalid" 191 "Invalid" 190 "Invalid" 189 "Invalid" 188 "Invalid" 187 "Invalid" 186 "Invalid" 185 "Invalid" 184 "Invalid" 183 "Invalid" 182 "Invalid" 181 "Invalid" 180 "Invalid" 179 "Invalid" 178 "Invalid" 177 "Invalid" 176 "Invalid" 175 "Invalid" 174 "Invalid" 173 "Invalid" 172 "Invalid" 171 "Invalid" 170 "Invalid" 169 "Invalid" 168 "Invalid" 167 "Invalid" 166 "Invalid" 165 "Invalid" 164 "Invalid" 163 "Invalid" 162 "Invalid" 161 "Invalid" ;
VAL_ 535 BCU_MinModlTmp 255 "Invalid" 254 "Invalid" 253 "Invalid" 252 "Invalid" 251 "Invalid" 250 "Invalid" 249 "Invalid" 248 "Invalid" 247 "Invalid" 246 "Invalid" 245 "Invalid" 244 "Invalid" 243 "Invalid" 242 "Invalid" 241 "Invalid" 240 "Invalid" 239 "Invalid" 238 "Invalid" 237 "Invalid" 236 "Invalid" 235 "Invalid" 234 "Invalid" 233 "Invalid" 232 "Invalid" 231 "Invalid" 230 "Invalid" 229 "Invalid" 228 "Invalid" 227 "Invalid" 226 "Invalid" 225 "Invalid" 224 "Invalid" 223 "Invalid" 222 "Invalid" 221 "Invalid" 220 "Invalid" 219 "Invalid" 218 "Invalid" 217 "Invalid" 216 "Invalid" 215 "Invalid" 214 "Invalid" 213 "Invalid" 212 "Invalid" 211 "Invalid" 210 "Invalid" 209 "Invalid" 208 "Invalid" 207 "Invalid" 206 "Invalid" 205 "Invalid" 204 "Invalid" 203 "Invalid" 202 "Invalid" 201 "Invalid" 200 "Invalid" 199 "Invalid" 198 "Invalid" 197 "Invalid" 196 "Invalid" 195 "Invalid" 194 "Invalid" 193 "Invalid" 192 "Invalid" 191 "Invalid" 190 "Invalid" 189 "Invalid" 188 "Invalid" 187 "Invalid" 186 "Invalid" 185 "Invalid" 184 "Invalid" 183 "Invalid" 182 "Invalid" 181 "Invalid" 180 "Invalid" 179 "Invalid" 178 "Invalid" 177 "Invalid" 176 "Invalid" 175 "Invalid" 174 "Invalid" 173 "Invalid" 172 "Invalid" 171 "Invalid" 170 "Invalid" 169 "Invalid" 168 "Invalid" 167 "Invalid" 166 "Invalid" 165 "Invalid" 164 "Invalid" 163 "Invalid" 162 "Invalid" 161 "Invalid" ;
VAL_ 535 BCU_MaxModlTmpNr 127 "Invalid" 126 "Invalid" 125 "Invalid" 124 "Invalid" 123 "Invalid" 122 "Invalid" 121 "Invalid" ;
VAL_ 535 BCU_MinModlTmpNr 127 "Invalid" 126 "Invalid" 125 "Invalid" 124 "Invalid" 123 "Invalid" 122 "Invalid" 121 "Invalid" ;
VAL_ 535 BCU_BattSilnTi 8191 "Invalid" 8190 "Invalid" 8189 "Invalid" 8188 "Invalid" 8187 "Invalid" 8186 "Invalid" 8185 "Invalid" 8184 "Invalid" 8183 "Invalid" 8182 "Invalid" 8181 "Invalid" 8180 "Invalid" 8179 "Invalid" 8178 "Invalid" 8177 "Invalid" 8176 "Invalid" 8175 "Invalid" 8174 "Invalid" 8173 "Invalid" 8172 "Invalid" 8171 "Invalid" 8170 "Invalid" 8169 "Invalid" 8168 "Invalid" 8167 "Invalid" 8166 "Invalid" 8165 "Invalid" 8164 "Invalid" 8163 "Invalid" 8162 "Invalid" 8161 "Invalid" 8160 "Invalid" 8159 "Invalid" 8158 "Invalid" 8157 "Invalid" 8156 "Invalid" 8155 "Invalid" 8154 "Invalid" 8153 "Invalid" 8152 "Invalid" 8151 "Invalid" 8150 "Invalid" 8149 "Invalid" 8148 "Invalid" 8147 "Invalid" 8146 "Invalid" 8145 "Invalid" 8144 "Invalid" 8143 "Invalid" 8142 "Invalid" 8141 "Invalid" 8140 "Invalid" 8139 "Invalid" 8138 "Invalid" 8137 "Invalid" 8136 "Invalid" 8135 "Invalid" 8134 "Invalid" 8133 "Invalid" 8132 "Invalid" 8131 "Invalid" 8130 "Invalid" 8129 "Invalid" 8128 "Invalid" 8127 "Invalid" 8126 "Invalid" 8125 "Invalid" 8124 "Invalid" 8123 "Invalid" 8122 "Invalid" 8121 "Invalid" 8120 "Invalid" 8119 "Invalid" 8118 "Invalid" 8117 "Invalid" 8116 "Invalid" 8115 "Invalid" 8114 "Invalid" 8113 "Invalid" 8112 "Invalid" 8111 "Invalid" 8110 "Invalid" 8109 "Invalid" 8108 "Invalid" 8107 "Invalid" 8106 "Invalid" 8105 "Invalid" 8104 "Invalid" 8103 "Invalid" 8102 "Invalid" 8101 "Invalid" 8100 "Invalid" 8099 "Invalid" 8098 "Invalid" 8097 "Invalid" 8096 "Invalid" 8095 "Invalid" 8094 "Invalid" 8093 "Invalid" 8092 "Invalid" 8091 "Invalid" 8090 "Invalid" 8089 "Invalid" 8088 "Invalid" 8087 "Invalid" 8086 "Invalid" 8085 "Invalid" 8084 "Invalid" 8083 "Invalid" 8082 "Invalid" 8081 "Invalid" 8080 "Invalid" 8079 "Invalid" 8078 "Invalid" 8077 "Invalid" 8076 "Invalid" 8075 "Invalid" 8074 "Invalid" 8073 "Invalid" 8072 "Invalid" 8071 "Invalid" 8070 "Invalid" 8069 "Invalid" 8068 "Invalid" 8067 "Invalid" 8066 "Invalid" 8065 "Invalid" 8064 "Invalid" 8063 "Invalid" 8062 "Invalid" 8061 "Invalid" 8060 "Invalid" 8059 "Invalid" 8058 "Invalid" 8057 "Invalid" 8056 "Invalid" 8055 "Invalid" 8054 "Invalid" 8053 "Invalid" 8052 "Invalid" 8051 "Invalid" 8050 "Invalid" 8049 "Invalid" 8048 "Invalid" 8047 "Invalid" 8046 "Invalid" 8045 "Invalid" 8044 "Invalid" 8043 "Invalid" 8042 "Invalid" 8041 "Invalid" 8040 "Invalid" 8039 "Invalid" 8038 "Invalid" 8037 "Invalid" 8036 "Invalid" 8035 "Invalid" 8034 "Invalid" 8033 "Invalid" 8032 "Invalid" 8031 "Invalid" 8030 "Invalid" 8029 "Invalid" 8028 "Invalid" 8027 "Invalid" 8026 "Invalid" 8025 "Invalid" 8024 "Invalid" 8023 "Invalid" 8022 "Invalid" 8021 "Invalid" 8020 "Invalid" 8019 "Invalid" 8018 "Invalid" 8017 "Invalid" 8016 "Invalid" 8015 "Invalid" 8014 "Invalid" 8013 "Invalid" 8012 "Invalid" 8011 "Invalid" 8010 "Invalid" 8009 "Invalid" 8008 "Invalid" 8007 "Invalid" 8006 "Invalid" 8005 "Invalid" 8004 "Invalid" 8003 "Invalid" 8002 "Invalid" 8001 "Invalid" ;
VAL_ 536 BCU_REESSFaultNr_RM 255 "Invalid" ;
VAL_ 536 BCU_SOH 127 "Invalid" 126 "Invalid" 125 "Invalid" 124 "Invalid" 123 "Invalid" 122 "Invalid" 121 "Invalid" 120 "Invalid" 119 "Invalid" 118 "Invalid" 117 "Invalid" 116 "Invalid" 115 "Invalid" 114 "Invalid" 113 "Invalid" 112 "Invalid" 111 "Invalid" 110 "Invalid" 109 "Invalid" 108 "Invalid" 107 "Invalid" 106 "Invalid" 105 "Invalid" 104 "Invalid" 103 "Invalid" 102 "Invalid" 101 "Invalid" ;
VAL_ 536 BCU_BattOverTmp 1 "Fault" 0 "Normal" ;
VAL_ 536 BCU_CellTmpOverWarn 1 "Fault" 0 "Normal" ;
VAL_ 536 BCU_CellVltUdrWarn 1 "Fault" 0 "Normal" ;
VAL_ 536 BCU_CellVltOverWarn 1 "Fault" 0 "Normal" ;
VAL_ 536 BCU_BattTmpDftlWarn 1 "Fault" 0 "Normal" ;
VAL_ 536 BCU_CellTmpUdrWarn 1 "Fault" 0 "Normal" ;
VAL_ 536 BCU_BattVltUnifWarn 1 "Fault" 0 "Normal" ;
VAL_ 536 BCU_BattVltDftlOverRg 1 "Fault" 0 "Normal" ;
VAL_ 536 BCU_BattVltUdrWarn 1 "Fault" 0 "Normal" ;
VAL_ 536 BCU_BattVltOverWarn 1 "Fault" 0 "Normal" ;
VAL_ 536 BCU_NvMemSts 1 "NVM Abnormal" 0 "NVM Normal" ;
VAL_ 536 BCU_SOCJumpWarn 1 "Fault" 0 "Normal" ;
VAL_ 536 BCU_SOCOverWarn 1 "Fault" 0 "Normal" ;
VAL_ 536 BCU_SOCLowWarn 1 "Fault" 0 "Normal" ;
VAL_ 536 BCU_BattTmpDftlWarn_RM 1 "Warning" 0 "Normal" ;
VAL_ 536 BCU_REESSNotMatch_RM 1 "Warning" 0 "Normal" ;
VAL_ 536 BCU_OverChrgWarn_RM 1 "warning" 0 "Normal" ;
VAL_ 536 BCU_ACChrgCntr 2047 "Invalid" 2046 "Invalid" 2045 "Invalid" 2044 "Invalid" 2043 "Invalid" 2042 "Invalid" 2041 "Invalid" 2040 "Invalid" 2039 "Invalid" 2038 "Invalid" 2037 "Invalid" 2036 "Invalid" 2035 "Invalid" 2034 "Invalid" 2033 "Invalid" 2032 "Invalid" 2031 "Invalid" 2030 "Invalid" 2029 "Invalid" 2028 "Invalid" 2027 "Invalid" 2026 "Invalid" 2025 "Invalid" 2024 "Invalid" 2023 "Invalid" 2022 "Invalid" 2021 "Invalid" 2020 "Invalid" 2019 "Invalid" 2018 "Invalid" 2017 "Invalid" 2016 "Invalid" 2015 "Invalid" 2014 "Invalid" 2013 "Invalid" 2012 "Invalid" 2011 "Invalid" 2010 "Invalid" 2009 "Invalid" 2008 "Invalid" 2007 "Invalid" 2006 "Invalid" 2005 "Invalid" 2004 "Invalid" 2003 "Invalid" 2002 "Invalid" 2001 "Invalid" ;
VAL_ 536 BCU_DCChrgrCntr 2047 "Invalid" 2046 "Invalid" 2045 "Invalid" 2044 "Invalid" 2043 "Invalid" 2042 "Invalid" 2041 "Invalid" 2040 "Invalid" 2039 "Invalid" 2038 "Invalid" 2037 "Invalid" 2036 "Invalid" 2035 "Invalid" 2034 "Invalid" 2033 "Invalid" 2032 "Invalid" 2031 "Invalid" 2030 "Invalid" 2029 "Invalid" 2028 "Invalid" 2027 "Invalid" 2026 "Invalid" 2025 "Invalid" 2024 "Invalid" 2023 "Invalid" 2022 "Invalid" 2021 "Invalid" 2020 "Invalid" 2019 "Invalid" 2018 "Invalid" 2017 "Invalid" 2016 "Invalid" 2015 "Invalid" 2014 "Invalid" 2013 "Invalid" 2012 "Invalid" 2011 "Invalid" 2010 "Invalid" 2009 "Invalid" 2008 "Invalid" 2007 "Invalid" 2006 "Invalid" 2005 "Invalid" 2004 "Invalid" 2003 "Invalid" 2002 "Invalid" 2001 "Invalid" ;
VAL_ 369 ESP_VhclSpd 8191 "Invalid" ;
VAL_ 369 ESP_VhclSpd_Vld 1 "Validity" 0 "Invalidity" ;
VAL_ 369 ESP_EPB_FltLamp 3 "Reserved" 2 "EPB failure lamp blinking" 1 "EPB failure lamp On" 0 "EPB failure lamp Off" ;
VAL_ 369 iB_BrkPedAppld 1 "BPA active" 0 "BPA inactive" ;
VAL_ 369 iB_BrkPedAppld_Q 3 "Not used" 2 "Faulty" 1 "Normal" 0 "Init" ;
VAL_ 657 iBCM_FL_TireP 255 "Invalid" ;
VAL_ 657 iBCM_FR_TireP 255 "Invalid" ;
VAL_ 657 iBCM_RL_TireP 255 "Invalid" ;
VAL_ 657 iBCM_RR_TireP 255 "Invalid" ;
VAL_ 657 iBCM_FL_TirePSts 3 "Reserved" 2 "Under-pressure" 1 "Over-pressure" 0 "Normal" ;
VAL_ 657 iBCM_FR_TirePSts 3 "Reserved" 2 "Under-pressure" 1 "Over-pressure" 0 "Normal" ;
VAL_ 657 iBCM_RL_TirePSts 3 "Reserved" 2 "Under-pressure" 1 "Over-pressure" 0 "Normal" ;
VAL_ 657 iBCM_RR_TirePSts 3 "Reserved" 2 "Under-pressure" 1 "Over-pressure" 0 "Normal" ;
VAL_ 658 iBCM_FL_TireTmp 255 "Invalid" ;
VAL_ 658 iBCM_FR_TireTmp 255 "Invalid" ;
VAL_ 658 iBCM_RL_TireTmp 255 "Invalid" ;
VAL_ 658 iBCM_RR_TireTmp 255 "Invalid" ;
VAL_ 658 iBCM_FL_TireTmpSts 1 "Over-temp" 0 "Normal" ;
VAL_ 658 iBCM_FR_TireTmpSts 1 "Over-temp" 0 "Normal" ;
VAL_ 658 iBCM_RL_TireTmpSts 1 "Over-temp" 0 "Normal" ;
VAL_ 658 iBCM_RR_TireTmpSts 1 "Over-temp" 0 "Normal" ;
VAL_ 658 iBCM_FL_FastLkg 1 "Fast Leakage" 0 "Not Fast Leakage" ;
VAL_ 658 iBCM_FR_FastLkg 1 "Fast Leakage" 0 "Not Fast Leakage" ;
VAL_ 658 iBCM_RL_FastLkg 1 "Fast Leakage" 0 "Not Fast Leakage" ;
VAL_ 658 iBCM_RR_FastLkg 1 "Fast Leakage" 0 "Not Fast Leakage" ;
VAL_ 656 iBCM_RemtLckUnlckStsFb 3 "Error" 2 "Unlock" 1 "Lock" 0 "No Action" ;
VAL_ 656 iBCM_BLELckUnlckStsFb 3 "Error" 2 "Unlock" 1 "Lock" 0 "No Action" ;
VAL_ 656 iBCM_RemtTrunkUnlckStsFb 3 "Reserved" 2 "Error" 1 "Unlock" 0 "No Action" ;
VAL_ 656 iBCM_BLETrunkUnlckStsFb 3 "Reserved" 2 "Error" 1 "Unlock" 0 "No Action" ;
VAL_ 656 iBCM_SchgCarStsFb 3 "Reserved" 2 "Error" 1 "Searched" 0 "No Action" ;
VAL_ 407 Clim_BlwrFlowDisp 15 "Reserved" 14 "Reserved" 13 "Reserved" 12 "Reserved" 11 "Reserved" 10 "Reserved" 9 "Reserved" 8 "Level 8" 7 "Level 7" 6 "Level 6" 5 "Level 5" 4 "Level 4" 3 "Level 3" 2 "Level 2" 1 "Level 1" 0 "Level 0" ;
VAL_ 407 Clim_PM25Disp 1023 "Invalid" 1022 "Invalid" 1021 "Invalid" 1020 "Invalid" 1019 "Invalid" 1018 "Invalid" 1017 "Invalid" 1016 "Invalid" 1015 "Invalid" 1014 "Invalid" 1013 "Invalid" 1012 "Invalid" 1011 "Invalid" 1010 "Invalid" 1009 "Invalid" 1008 "Invalid" 1007 "Invalid" 1006 "Invalid" 1005 "Invalid" 1004 "Invalid" 1003 "Invalid" 1002 "Invalid" 1001 "Invalid" 1000 "Invalid" ;
VAL_ 407 Clim_OutsideTmpVld 1 "Validity" 0 "Invalidity" ;
VAL_ 407 Clim_InsideTmpVld 1 "Validity" 0 "Invalidity" ;
VAL_ 407 Clim_InsideTmp 2047 "Invalid" 2046 "Invalid" 2045 "Invalid" 2044 "Invalid" 2043 "Invalid" 2042 "Invalid" 2041 "Invalid" 2040 "Invalid" 2039 "Invalid" 2038 "Invalid" 2037 "Invalid" 2036 "Invalid" 2035 "Invalid" 2034 "Invalid" 2033 "Invalid" 2032 "Invalid" 2031 "Invalid" 2030 "Invalid" 2029 "Invalid" 2028 "Invalid" 2027 "Invalid" 2026 "Invalid" 2025 "Invalid" 2024 "Invalid" 2023 "Invalid" 2022 "Invalid" 2021 "Invalid" 2020 "Invalid" 2019 "Invalid" 2018 "Invalid" 2017 "Invalid" 2016 "Invalid" 2015 "Invalid" 2014 "Invalid" 2013 "Invalid" 2012 "Invalid" 2011 "Invalid" 2010 "Invalid" 2009 "Invalid" 2008 "Invalid" 2007 "Invalid" 2006 "Invalid" 2005 "Invalid" 2004 "Invalid" 2003 "Invalid" 2002 "Invalid" 2001 "Invalid" 2000 "Invalid" 1999 "Invalid" 1998 "Invalid" 1997 "Invalid" 1996 "Invalid" 1995 "Invalid" 1994 "Invalid" 1993 "Invalid" 1992 "Invalid" 1991 "Invalid" 1990 "Invalid" 1989 "Invalid" 1988 "Invalid" 1987 "Invalid" 1986 "Invalid" 1985 "Invalid" 1984 "Invalid" 1983 "Invalid" 1982 "Invalid" 1981 "Invalid" 1980 "Invalid" 1979 "Invalid" 1978 "Invalid" 1977 "Invalid" 1976 "Invalid" 1975 "Invalid" 1974 "Invalid" 1973 "Invalid" 1972 "Invalid" 1971 "Invalid" 1970 "Invalid" 1969 "Invalid" 1968 "Invalid" 1967 "Invalid" 1966 "Invalid" 1965 "Invalid" 1964 "Invalid" 1963 "Invalid" 1962 "Invalid" 1961 "Invalid" 1960 "Invalid" 1959 "Invalid" 1958 "Invalid" 1957 "Invalid" 1956 "Invalid" 1955 "Invalid" 1954 "Invalid" 1953 "Invalid" 1952 "Invalid" 1951 "Invalid" 1950 "Invalid" 1949 "Invalid" 1948 "Invalid" 1947 "Invalid" 1946 "Invalid" 1945 "Invalid" 1944 "Invalid" 1943 "Invalid" 1942 "Invalid" 1941 "Invalid" 1940 "Invalid" 1939 "Invalid" 1938 "Invalid" 1937 "Invalid" 1936 "Invalid" 1935 "Invalid" 1934 "Invalid" 1933 "Invalid" 1932 "Invalid" 1931 "Invalid" 1930 "Invalid" 1929 "Invalid" 1928 "Invalid" 1927 "Invalid" 1926 "Invalid" 1925 "Invalid" 1924 "Invalid" 1923 "Invalid" 1922 "Invalid" 1921 "Invalid" 1920 "Invalid" 1919 "Invalid" 1918 "Invalid" 1917 "Invalid" 1916 "Invalid" 1915 "Invalid" 1914 "Invalid" 1913 "Invalid" 1912 "Invalid" 1911 "Invalid" 1910 "Invalid" 1909 "Invalid" 1908 "Invalid" 1907 "Invalid" 1906 "Invalid" 1905 "Invalid" 1904 "Invalid" 1903 "Invalid" 1902 "Invalid" 1901 "Invalid" 1900 "Invalid" 1899 "Invalid" 1898 "Invalid" 1897 "Invalid" 1896 "Invalid" 1895 "Invalid" 1894 "Invalid" 1893 "Invalid" 1892 "Invalid" 1891 "Invalid" 1890 "Invalid" 1889 "Invalid" 1888 "Invalid" 1887 "Invalid" 1886 "Invalid" 1885 "Invalid" 1884 "Invalid" 1883 "Invalid" 1882 "Invalid" 1881 "Invalid" 1880 "Invalid" 1879 "Invalid" 1878 "Invalid" 1877 "Invalid" 1876 "Invalid" 1875 "Invalid" 1874 "Invalid" 1873 "Invalid" 1872 "Invalid" 1871 "Invalid" 1870 "Invalid" 1869 "Invalid" 1868 "Invalid" 1867 "Invalid" 1866 "Invalid" 1865 "Invalid" 1864 "Invalid" 1863 "Invalid" 1862 "Invalid" 1861 "Invalid" 1860 "Invalid" 1859 "Invalid" 1858 "Invalid" 1857 "Invalid" 1856 "Invalid" 1855 "Invalid" 1854 "Invalid" 1853 "Invalid" 1852 "Invalid" 1851 "Invalid" 1850 "Invalid" 1849 "Invalid" 1848 "Invalid" 1847 "Invalid" 1846 "Invalid" 1845 "Invalid" 1844 "Invalid" 1843 "Invalid" 1842 "Invalid" 1841 "Invalid" 1840 "Invalid" 1839 "Invalid" 1838 "Invalid" 1837 "Invalid" 1836 "Invalid" 1835 "Invalid" 1834 "Invalid" 1833 "Invalid" 1832 "Invalid" 1831 "Invalid" 1830 "Invalid" 1829 "Invalid" 1828 "Invalid" 1827 "Invalid" 1826 "Invalid" 1825 "Invalid" 1824 "Invalid" 1823 "Invalid" 1822 "Invalid" 1821 "Invalid" 1820 "Invalid" 1819 "Invalid" 1818 "Invalid" 1817 "Invalid" 1816 "Invalid" 1815 "Invalid" 1814 "Invalid" 1813 "Invalid" 1812 "Invalid" 1811 "Invalid" 1810 "Invalid" 1809 "Invalid" 1808 "Invalid" 1807 "Invalid" 1806 "Invalid" 1805 "Invalid" 1804 "Invalid" 1803 "Invalid" 1802 "Invalid" 1801 "Invalid" 1800 "Invalid" 1799 "Invalid" 1798 "Invalid" 1797 "Invalid" 1796 "Invalid" 1795 "Invalid" 1794 "Invalid" 1793 "Invalid" 1792 "Invalid" 1791 "Invalid" 1790 "Invalid" 1789 "Invalid" 1788 "Invalid" 1787 "Invalid" 1786 "Invalid" 1785 "Invalid" 1784 "Invalid" 1783 "Invalid" 1782 "Invalid" 1781 "Invalid" 1780 "Invalid" 1779 "Invalid" 1778 "Invalid" 1777 "Invalid" 1776 "Invalid" 1775 "Invalid" 1774 "Invalid" 1773 "Invalid" 1772 "Invalid" 1771 "Invalid" 1770 "Invalid" 1769 "Invalid" 1768 "Invalid" 1767 "Invalid" 1766 "Invalid" 1765 "Invalid" 1764 "Invalid" 1763 "Invalid" 1762 "Invalid" 1761 "Invalid" 1760 "Invalid" 1759 "Invalid" 1758 "Invalid" 1757 "Invalid" 1756 "Invalid" 1755 "Invalid" 1754 "Invalid" 1753 "Invalid" 1752 "Invalid" 1751 "Invalid" 1750 "Invalid" 1749 "Invalid" 1748 "Invalid" 1747 "Invalid" 1746 "Invalid" 1745 "Invalid" 1744 "Invalid" 1743 "Invalid" 1742 "Invalid" 1741 "Invalid" 1740 "Invalid" 1739 "Invalid" 1738 "Invalid" 1737 "Invalid" 1736 "Invalid" 1735 "Invalid" 1734 "Invalid" 1733 "Invalid" 1732 "Invalid" 1731 "Invalid" 1730 "Invalid" 1729 "Invalid" 1728 "Invalid" 1727 "Invalid" 1726 "Invalid" 1725 "Invalid" 1724 "Invalid" 1723 "Invalid" 1722 "Invalid" 1721 "Invalid" 1720 "Invalid" 1719 "Invalid" 1718 "Invalid" 1717 "Invalid" 1716 "Invalid" 1715 "Invalid" 1714 "Invalid" 1713 "Invalid" 1712 "Invalid" 1711 "Invalid" 1710 "Invalid" 1709 "Invalid" 1708 "Invalid" 1707 "Invalid" 1706 "Invalid" 1705 "Invalid" 1704 "Invalid" 1703 "Invalid" 1702 "Invalid" 1701 "Invalid" 1700 "Invalid" 1699 "Invalid" 1698 "Invalid" 1697 "Invalid" 1696 "Invalid" 1695 "Invalid" 1694 "Invalid" 1693 "Invalid" 1692 "Invalid" 1691 "Invalid" 1690 "Invalid" 1689 "Invalid" 1688 "Invalid" 1687 "Invalid" 1686 "Invalid" 1685 "Invalid" 1684 "Invalid" 1683 "Invalid" 1682 "Invalid" 1681 "Invalid" 1680 "Invalid" 1679 "Invalid" 1678 "Invalid" 1677 "Invalid" 1676 "Invalid" 1675 "Invalid" 1674 "Invalid" 1673 "Invalid" 1672 "Invalid" 1671 "Invalid" 1670 "Invalid" 1669 "Invalid" 1668 "Invalid" 1667 "Invalid" 1666 "Invalid" 1665 "Invalid" 1664 "Invalid" 1663 "Invalid" 1662 "Invalid" 1661 "Invalid" 1660 "Invalid" 1659 "Invalid" 1658 "Invalid" 1657 "Invalid" 1656 "Invalid" 1655 "Invalid" 1654 "Invalid" 1653 "Invalid" 1652 "Invalid" 1651 "Invalid" 1650 "Invalid" 1649 "Invalid" 1648 "Invalid" 1647 "Invalid" 1646 "Invalid" 1645 "Invalid" 1644 "Invalid" 1643 "Invalid" 1642 "Invalid" 1641 "Invalid" 1640 "Invalid" 1639 "Invalid" 1638 "Invalid" 1637 "Invalid" 1636 "Invalid" 1635 "Invalid" 1634 "Invalid" 1633 "Invalid" 1632 "Invalid" 1631 "Invalid" 1630 "Invalid" 1629 "Invalid" 1628 "Invalid" 1627 "Invalid" 1626 "Invalid" 1625 "Invalid" 1624 "Invalid" 1623 "Invalid" 1622 "Invalid" 1621 "Invalid" 1620 "Invalid" 1619 "Invalid" 1618 "Invalid" 1617 "Invalid" 1616 "Invalid" 1615 "Invalid" 1614 "Invalid" 1613 "Invalid" 1612 "Invalid" 1611 "Invalid" 1610 "Invalid" 1609 "Invalid" 1608 "Invalid" 1607 "Invalid" 1606 "Invalid" 1605 "Invalid" 1604 "Invalid" 1603 "Invalid" 1602 "Invalid" 1601 "Invalid" ;
VAL_ 407 Clim_RemtClimStsFb 7 "Reserved" 6 "Reserved" 5 "Reserved" 4 "Reserved" 3 "Reserved" 2 "Clim Error" 1 "On" 0 "Off" ;
VAL_ 654 Clim_PM25SwchSts 1 "On" 0 "Off" ;
VAL_ 654 Clim_AnionGenSwchSts 1 "On" 0 "Off" ;
VAL_ 654 DSM_RemtSeatHeatgStsFb 3 "Reserved" 2 "Error" 1 "On" 0 "Off" ;
VAL_ 654 FLW_FLDoorWindowsPosition 15 "Reserved" 14 "Reserved" 13 "Reserved" 12 "Reserved" 11 "Reserved" 10 "Reserved" 9 "Reserved" 8 "Fully open" 7 "Between large mid-opening and fully open" 6 "Large mid-opening position" 5 "Between slight opening and large mid-opening" 4 "Slight opening" 3 "Between short drop position and slight opening" 2 "Short drop position" 1 "Between closed and short drop position" 0 "Closed" ;
VAL_ 654 FRW_FRDoorWindowsPosition 15 "Reserved" 14 "Reserved" 13 "Reserved" 12 "Reserved" 11 "Reserved" 10 "Reserved" 9 "Reserved" 8 "Fully open" 7 "Between large mid-opening and fully open" 6 "Large mid-opening position" 5 "Between slight opening and large mid-opening" 4 "Slight opening" 3 "Between short drop position and slight opening" 2 "Short drop position" 1 "Between closed and short drop position" 0 "Closed" ;
VAL_ 654 RLW_RLDoorWindowsPosition 15 "Reserved" 14 "Reserved" 13 "Reserved" 12 "Reserved" 11 "Reserved" 10 "Reserved" 9 "Reserved" 8 "Fully open" 7 "Between large mid-opening and fully open" 6 "Large mid-opening position" 5 "Between slight opening and large mid-opening" 4 "Slight opening" 3 "Between short drop position and slight opening" 2 "Short drop position" 1 "Between closed and short drop position" 0 "Closed" ;
VAL_ 654 RRW_RRDoorWindowsPosition 15 "Reserved" 14 "Reserved" 13 "Reserved" 12 "Reserved" 11 "Reserved" 10 "Reserved" 9 "Reserved" 8 "Fully open" 7 "Between large mid-opening and fully open" 6 "Large mid-opening position" 5 "Between slight opening and large mid-opening" 4 "Slight opening" 3 "Between short drop position and slight opening" 2 "Short drop position" 1 "Between closed and short drop position" 0 "Closed" ;
VAL_ 654 SR_SrPosition 7 "Uninitialized" 6 "Fully open" 5 "Partially slide" 4 "Antipinch in partially slide" 3 "Fully close" 2 "Antipinch in vent" 1 "Vent area" 0 "Tilt up" ;
VAL_ 400 iBCM_AntitheftSts 3 "Alarmed" 2 "Prearmed" 1 "Armed" 0 "Disarmed" ;
VAL_ 400 iBCM_PwrMod 3 "Reserved" 2 "ON" 1 "ACC" 0 "OFF" ;
VAL_ 400 iBCM_VhclDoorLckSts 1 "Lock" 0 "Unlock" ;
VAL_ 400 iBCM_FL_DoorAjarSts 1 "Open" 0 "Close" ;
VAL_ 400 iBCM_FR_DoorAjarSts 1 "Open" 0 "Close" ;
VAL_ 400 iBCM_RL_DoorAjarSts 1 "Open" 0 "Close" ;
VAL_ 400 iBCM_RR_DoorAjarSts 1 "Open" 0 "Close" ;
